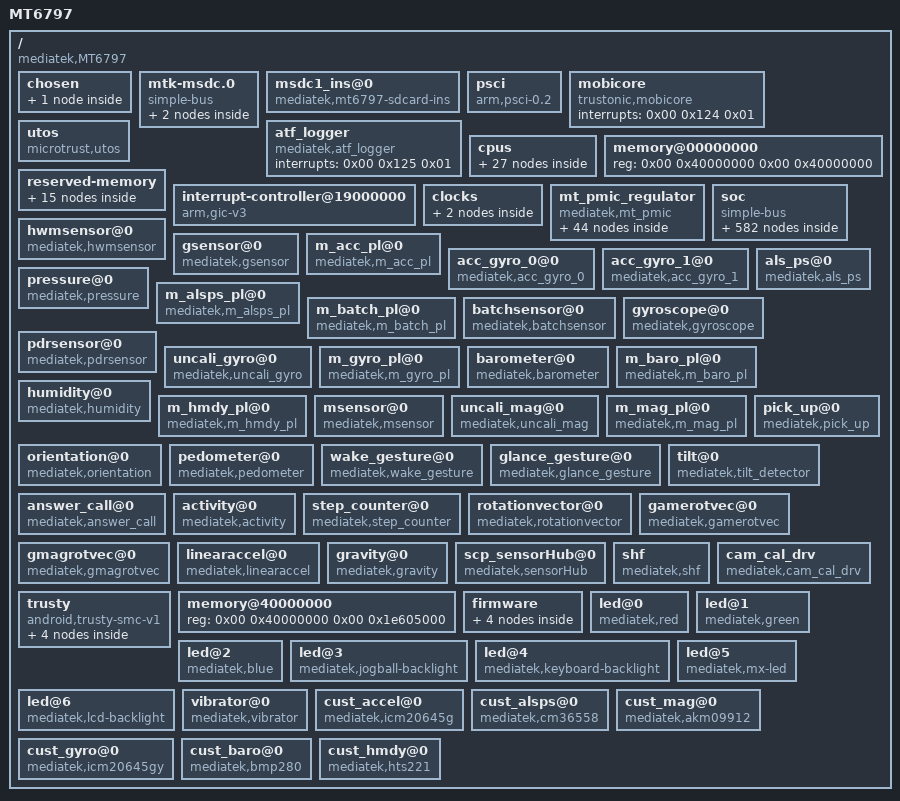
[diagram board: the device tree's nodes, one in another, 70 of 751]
/dts-v1/;

/ {
	model = "MT6797";
	compatible = "mediatek,MT6797";
	interrupt-parent = <0x01>;
	#address-cells = <0x02>;
	#size-cells = <0x02>;

	chosen {
		bootargs = "console=tty0 console=ttyMT0,921600n1 root=/dev/ram initrd=0x44000000,0x4B434E loglevel=8";
		atag,videolfb-fb_base_h = <0x00>;
		atag,videolfb-fb_base_l = "^`P";
		atag,videolfb-islcmfound = <0x01>;
		atag,videolfb-islcm_inited = <0x00>;
		atag,videolfb-fps = <0x1770>;
		atag,videolfb-vramSize = <0x17bb000>;
		atag,videolfb-lcmname = "ft8716_fhd_vdo_sharp";

		linux,sysrq-reset-seq {
			keyset = <0x66 0x72 0x73>;
			timeout-ms = <0x3a98>;
		};
	};

	mtk-msdc.0 {
		compatible = "simple-bus";
		#address-cells = <0x01>;
		#size-cells = <0x01>;
		ranges = <0x00 0x00 0x00 0xffffffff>;

		msdc0@11230000 {
			compatible = "mediatek,mt6797-mmc";
			reg = <0x11230000 0x10000>;
			interrupts = <0x00 0x4f 0x08>;
			clocks = <0x02 0x21>;
			clock-names = "msdc0-clock";
			status = "okay";
			clk_src = [01];
			bus-width = <0x08>;
			max-frequency = <0xbebc200>;
			cap-mmc-highspeed;
			msdc-sys-suspend;
			mmc-ddr-1_8v;
			mmc-hs200-1_8v;
			mmc-hs400-1_8v;
			non-removable;
			pinctl = <0x03>;
			register_setting = <0x04>;
			host_function = [00];
			bootable;
		};

		msdc1@11240000 {
			compatible = "mediatek,mt6797-mmc";
			reg = <0x11240000 0x10000>;
			interrupts = <0x00 0x50 0x08>;
			clocks = <0x02 0x23>;
			clock-names = "msdc1-clock";
			status = "disabled";
			clk_src = [02];
			bus-width = <0x04>;
			max-frequency = <0xbebc200>;
			msdc-sys-suspend;
			cap-sd-highspeed;
			sd-uhs-sdr12;
			sd-uhs-sdr25;
			sd-uhs-sdr50;
			sd-uhs-sdr104;
			pinctl = <0x05>;
			pinctl_sdr104 = <0x06>;
			pinctl_sdr50 = <0x07>;
			pinctl_ddr50 = <0x08>;
			register_setting = <0x09>;
			host_function = [01];
			cd_level = [00];
			cd-gpios = <0x0a 0x43 0x00>;
		};
	};

	msdc1_ins@0 {
		compatible = "mediatek,mt6797-sdcard-ins";
	};

	psci {
		compatible = "arm,psci-0.2";
		method = "smc";
		cpu_suspend = <0x84000001>;
		cpu_off = <0x84000002>;
		cpu_on = <0x84000003>;
		affinity_info = <0x84000004>;
	};

	mobicore {
		compatible = "trustonic,mobicore";
		interrupts = <0x00 0x124 0x01>;
	};

	atf_logger {
		compatible = "mediatek,atf_logger";
		interrupts = <0x00 0x125 0x01>;
	};

	utos {
		compatible = "microtrust,utos";
		interrupts = <0x00 0x126 0x01 0x00 0x127 0x01 0x00 0x128 0x01 0x00 0x12c 0x01 0x00 0x12d 0x01 0x00 0x12e 0x01 0x00 0x12f 0x01 0x00 0x131 0x01>;
	};

	cpus {
		#address-cells = <0x01>;
		#size-cells = <0x00>;

		cpu@000 {
			device_type = "cpu";
			compatible = "arm,cortex-a53";
			reg = <0x00>;
			enable-method = "psci";
			cpu-idle-states = <0x0b 0x0b 0x0b 0x0c 0x0c 0x0c>;
			cpu-release-addr = <0x00 0x40000200>;
			clock-frequency = <0x52e8f9c0>;
			linux,phandle = <0x0d>;
			phandle = <0x0d>;
		};

		cpu@001 {
			device_type = "cpu";
			compatible = "arm,cortex-a53";
			reg = <0x01>;
			enable-method = "psci";
			cpu-idle-states = <0x0b 0x0b 0x0b 0x0c 0x0c 0x0c>;
			cpu-release-addr = <0x00 0x40000200>;
			clock-frequency = <0x52e8f9c0>;
			linux,phandle = <0x0e>;
			phandle = <0x0e>;
		};

		cpu@002 {
			device_type = "cpu";
			compatible = "arm,cortex-a53";
			reg = <0x02>;
			enable-method = "psci";
			cpu-idle-states = <0x0b 0x0b 0x0b 0x0c 0x0c 0x0c>;
			cpu-release-addr = <0x00 0x40000200>;
			clock-frequency = <0x52e8f9c0>;
			linux,phandle = <0x0f>;
			phandle = <0x0f>;
		};

		cpu@003 {
			device_type = "cpu";
			compatible = "arm,cortex-a53";
			reg = <0x03>;
			enable-method = "psci";
			cpu-idle-states = <0x0b 0x0b 0x0b 0x0c 0x0c 0x0c>;
			cpu-release-addr = <0x00 0x40000200>;
			clock-frequency = <0x52e8f9c0>;
			linux,phandle = <0x10>;
			phandle = <0x10>;
		};

		cpu@100 {
			device_type = "cpu";
			compatible = "arm,cortex-a53";
			reg = <0x100>;
			enable-method = "psci";
			cpu-idle-states = <0x0b 0x0b 0x0b 0x0c 0x0c 0x0c>;
			cpu-release-addr = <0x00 0x40000200>;
			clock-frequency = <0x743aa380>;
			linux,phandle = <0x11>;
			phandle = <0x11>;
		};

		cpu@101 {
			device_type = "cpu";
			compatible = "arm,cortex-a53";
			reg = <0x101>;
			enable-method = "psci";
			cpu-idle-states = <0x0b 0x0b 0x0b 0x0c 0x0c 0x0c>;
			cpu-release-addr = <0x00 0x40000200>;
			clock-frequency = <0x743aa380>;
			linux,phandle = <0x12>;
			phandle = <0x12>;
		};

		cpu@102 {
			device_type = "cpu";
			compatible = "arm,cortex-a53";
			reg = <0x102>;
			enable-method = "psci";
			cpu-idle-states = <0x0b 0x0b 0x0b 0x0c 0x0c 0x0c>;
			cpu-release-addr = <0x00 0x40000200>;
			clock-frequency = <0x743aa380>;
			linux,phandle = <0x13>;
			phandle = <0x13>;
		};

		cpu@103 {
			device_type = "cpu";
			compatible = "arm,cortex-a53";
			reg = <0x103>;
			enable-method = "psci";
			cpu-idle-states = <0x0b 0x0b 0x0b 0x0c 0x0c 0x0c>;
			cpu-release-addr = <0x00 0x40000200>;
			clock-frequency = <0x743aa380>;
			linux,phandle = <0x14>;
			phandle = <0x14>;
		};

		cpu@200 {
			device_type = "cpu";
			compatible = "arm,cortex-a72";
			reg = <0x200>;
			enable-method = "psci";
			cpu-idle-states = <0x0b 0x0b 0x0b 0x0c 0x0c 0x0c>;
			cpu-release-addr = <0x00 0x40000200>;
			clock-frequency = <0x88601c00>;
			linux,phandle = <0x15>;
			phandle = <0x15>;
		};

		cpu@201 {
			device_type = "cpu";
			compatible = "arm,cortex-a72";
			reg = <0x201>;
			enable-method = "psci";
			cpu-idle-states = <0x0b 0x0b 0x0b 0x0c 0x0c 0x0c>;
			cpu-release-addr = <0x00 0x40000200>;
			clock-frequency = <0x88601c00>;
			linux,phandle = <0x16>;
			phandle = <0x16>;
		};

		cpu-map {

			cluster0 {

				core0 {
					cpu = <0x0d>;
				};

				core1 {
					cpu = <0x0e>;
				};

				core2 {
					cpu = <0x0f>;
				};

				core3 {
					cpu = <0x10>;
				};
			};

			cluster1 {

				core0 {
					cpu = <0x11>;
				};

				core1 {
					cpu = <0x12>;
				};

				core2 {
					cpu = <0x13>;
				};

				core3 {
					cpu = <0x14>;
				};
			};

			cluster2 {

				core0 {
					cpu = <0x15>;
				};

				core1 {
					cpu = <0x16>;
				};
			};
		};

		idle-states {
			entry-method = "arm,psci";

			cpu-sleep-0-0 {
				compatible = "arm,idle-state";
				arm,psci-suspend-param = <0x10000>;
				entry-latency-us = <0x258>;
				exit-latency-us = <0x258>;
				min-residency-us = <0x4b0>;
				linux,phandle = <0x0c>;
				phandle = <0x0c>;
			};

			cluster-sleep-0 {
				compatible = "arm,idle-state";
				arm,psci-suspend-param = <0x1010000>;
				entry-latency-us = <0x320>;
				exit-latency-us = <0x3e8>;
				min-residency-us = <0x7d0>;
				linux,phandle = <0x0b>;
				phandle = <0x0b>;
			};
		};
	};

	memory@00000000 {
		device_type = "memory";
		reg = <0x00 0x40000000 0x00 0x40000000>;
	};

	reserved-memory {
		#address-cells = <0x02>;
		#size-cells = <0x02>;
		ranges;

		spm-dummy-1@40000000 {
			compatible = "mediatek,spm-dummy-1";
			reg = <0x00 0x40000000 0x00 0x1000>;
		};

		reserve-memory-ccci_md1 {
			compatible = "mediatek,reserve-memory-ccci_md1";
			no-map;
			size = <0x00 0xa100000>;
			alignment = <0x00 0x2000000>;
			alloc-ranges = <0x00 0x40000000 0x00 0x80000000>;
		};

		reserve-memory-ccci_share {
			compatible = "mediatek,reserve-memory-ccci_share";
			no-map;
			size = <0x00 0x600000>;
			alignment = <0x00 0x4000000>;
			alloc-ranges = <0x00 0x40000000 0x00 0x50000000>;
		};

		minirdump-reserved-memory@444f0000 {
			compatible = "minirdump-reserve-memory";
			reg = <0x00 0x444f0000 0x00 0x10000>;
		};

		preloader-reserved-memory@44800000 {
			compatible = "mediatek,preloader";
			reg = <0x00 0x44800000 0x00 0x100000>;
		};

		lk-reserved-memory@46000000 {
			compatible = "mediatek,lk";
			reg = <0x00 0x46000000 0x00 0x400000>;
		};

		ram_console-reserved-memory@44400000 {
			compatible = "ram_console-reserve-memory";
			reg = <0x00 0x44400000 0x00 0x10000>;
		};

		pstore-reserved-memory@44410000 {
			compatible = "mediatek,pstore";
			reg = <0x00 0x44410000 0x00 0xe0000>;
		};

		consys-reserve-memory {
			compatible = "mediatek,consys-reserve-memory";
			no-map;
			size = <0x00 0x200000>;
			alignment = <0x00 0x200000>;
			alloc-ranges = <0x00 0x40000000 0x00 0x80000000>;
		};

		spm-reserve-memory {
			compatible = "mediatek,spm-reserve-memory";
			no-map;
			size = <0x00 0x16000>;
			alignment = <0x00 0x10000>;
			alloc-ranges = <0x00 0x40000000 0x00 0x80000000>;
		};

		atf-reserved-memory@44600000 {
			compatible = "mediatek,mt6797-atf-reserved-memory";
			no-map;
			reg = <0x00 0x44600000 0x00 0x10000>;
		};

		atf-ramdump-memory@44610000 {
			compatible = "mediatek,mt6797-atf-ramdump-memory";
			no-map;
			reg = <0x00 0x44610000 0x00 0x30000>;
		};

		cache-dump-memory@44640000 {
			compatible = "mediatek,cache-dump-memory";
			no-map;
			reg = <0x00 0x44640000 0x00 0x30000>;
		};

		reserve-memory-scp_share {
			compatible = "mediatek,reserve-memory-scp_share";
			no-map;
			size = <0x00 0x1000000>;
			alignment = <0x00 0x1000000>;
			alloc-ranges = <0x00 0x40000000 0x00 0x50000000>;
		};

		memory-lowpower-reserved-memory {
			compatible = "mediatek,memory-lowpower";
			size = <0x00 0x40000000>;
			alloc-ranges = <0x00 0xc0000000 0x00 0x80000000>;
		};
	};

	interrupt-controller@19000000 {
		compatible = "arm,gic-v3";
		#interrupt-cells = <0x03>;
		#address-cells = <0x02>;
		#size-cells = <0x02>;
		#redistributor-regions = <0x01>;
		interrupt-controller;
		reg = <0x00 0x19000000 0x00 0x40000 0x00 0x19200000 0x00 0x200000 0x00 0x10220620 0x00 0x1000 0x00 0x10220690 0x00 0x1000>;
		interrupts = <0x01 0x09 0x04>;
		mediatek,wdt_irq = <0xa9>;
		mediatek,reg_len_pol0 = <0x08>;
		linux,phandle = <0x01>;
		phandle = <0x01>;
	};

	clocks {

		clk_null {
			compatible = "fixed-clock";
			#clock-cells = <0x00>;
			clock-frequency = <0x00>;
		};

		clk26m {
			compatible = "fixed-clock";
			#clock-cells = <0x00>;
			clock-frequency = <0x18cba80>;
			linux,phandle = <0x5b>;
			phandle = <0x5b>;
		};
	};

	mt_pmic_regulator {
		compatible = "mediatek,mt_pmic";

		buck_regulators {
			compatible = "mediatek,mt_pmic_buck_regulators";

			buck_vcore {
				regulator-name = "vcore";
				regulator-min-microvolt = <0x927c0>;
				regulator-max-microvolt = <0x154456>;
				regulator-ramp-delay = <0x186a>;
				regulator-enable-ramp-delay = <0xb4>;
			};

			buck_vgpu {
				regulator-name = "vgpu";
				regulator-min-microvolt = <0x927c0>;
				regulator-max-microvolt = <0x154456>;
				regulator-ramp-delay = <0x186a>;
				regulator-enable-ramp-delay = <0xb4>;
				regulator-always-on;
				regulator-boot-on;
			};

			buck_vmodem {
				regulator-name = "vmodem";
				regulator-min-microvolt = <0x927c0>;
				regulator-max-microvolt = <0x154456>;
				regulator-ramp-delay = <0x186a>;
				regulator-enable-ramp-delay = <0xb4>;
				regulator-always-on;
				regulator-boot-on;
			};

			buck_vmd1 {
				regulator-name = "vmd1";
				regulator-min-microvolt = <0x927c0>;
				regulator-max-microvolt = <0x154456>;
				regulator-ramp-delay = <0x186a>;
				regulator-enable-ramp-delay = <0xb4>;
				regulator-always-on;
				regulator-boot-on;
			};

			buck_vsram_md {
				regulator-name = "vsram_md";
				regulator-min-microvolt = <0x927c0>;
				regulator-max-microvolt = <0x154456>;
				regulator-ramp-delay = <0x186a>;
				regulator-enable-ramp-delay = <0xb4>;
				regulator-always-on;
				regulator-boot-on;
			};

			buck_vs1 {
				regulator-name = "vs1";
				regulator-min-microvolt = <0x927c0>;
				regulator-max-microvolt = <0x154456>;
				regulator-ramp-delay = <0x186a>;
				regulator-enable-ramp-delay = <0xb4>;
				regulator-always-on;
				regulator-boot-on;
			};

			buck_vs2 {
				regulator-name = "vs2";
				regulator-min-microvolt = <0x927c0>;
				regulator-max-microvolt = <0x154456>;
				regulator-ramp-delay = <0x186a>;
				regulator-enable-ramp-delay = <0xb4>;
				regulator-always-on;
				regulator-boot-on;
			};

			buck_vpa {
				regulator-name = "vpa";
				regulator-min-microvolt = <0x927c0>;
				regulator-max-microvolt = <0x154456>;
				regulator-ramp-delay = <0x186a>;
				regulator-enable-ramp-delay = <0xb4>;
				regulator-always-on;
				regulator-boot-on;
			};

			buck_vsram_proc {
				regulator-name = "vsram_proc";
				regulator-min-microvolt = <0x927c0>;
				regulator-max-microvolt = <0x154456>;
				regulator-ramp-delay = <0x186a>;
				regulator-enable-ramp-delay = <0xb4>;
				regulator-always-on;
				regulator-boot-on;
			};
		};

		ldo_regulators {
			compatible = "mediatek,mt_pmic_ldo_regulators";

			ldo_va18 {
				regulator-name = "va18";
				regulator-min-microvolt = <0x1b7740>;
				regulator-max-microvolt = <0x1b7740>;
				regulator-enable-ramp-delay = <0x108>;
				regulator-boot-on;
				linux,phandle = <0x17>;
				phandle = <0x17>;
			};

			ldo_vtcxo24 {
				regulator-name = "vtcxo24";
				regulator-min-microvolt = <0x1b7740>;
				regulator-max-microvolt = <0x2ab980>;
				regulator-enable-ramp-delay = <0x6e>;
				regulator-boot-on;
				linux,phandle = <0x18>;
				phandle = <0x18>;
			};

			ldo_vtcxo28 {
				regulator-name = "vtcxo28";
				regulator-min-microvolt = <0x1b7740>;
				regulator-max-microvolt = <0x2ab980>;
				regulator-enable-ramp-delay = <0x6e>;
				linux,phandle = <0x19>;
				phandle = <0x19>;
			};

			ldo_vcn28 {
				regulator-name = "vcn28";
				regulator-min-microvolt = <0x1b7740>;
				regulator-max-microvolt = <0x2ab980>;
				regulator-enable-ramp-delay = <0x108>;
				linux,phandle = <0x2b>;
				phandle = <0x2b>;
			};

			ldo_vcama {
				regulator-name = "vcama";
				regulator-min-microvolt = <0x16e360>;
				regulator-max-microvolt = <0x2ab980>;
				regulator-enable-ramp-delay = <0x108>;
				regulator-default-on = <0x01>;
				status = "okay";
				linux,phandle = <0x7d>;
				phandle = <0x7d>;
			};

			ldo_vusb33 {
				regulator-name = "vusb33";
				regulator-min-microvolt = <0x325aa0>;
				regulator-max-microvolt = <0x325aa0>;
				regulator-enable-ramp-delay = <0x108>;
				regulator-boot-on;
			};

			ldo_vsim1 {
				regulator-name = "vsim1";
				regulator-min-microvolt = <0x19f0a0>;
				regulator-max-microvolt = <0x2f4d60>;
				regulator-enable-ramp-delay = <0x108>;
				regulator-default-on = <0x01>;
				status = "okay";
				linux,phandle = <0x1a>;
				phandle = <0x1a>;
			};

			ldo_vsim2 {
				regulator-name = "vsim2";
				regulator-min-microvolt = <0x19f0a0>;
				regulator-max-microvolt = <0x2f4d60>;
				regulator-enable-ramp-delay = <0x108>;
				regulator-default-on = <0x01>;
				status = "okay";
				linux,phandle = <0x1b>;
				phandle = <0x1b>;
			};

			ldo_vemc {
				regulator-name = "vemc_3v3";
				regulator-min-microvolt = <0x2dc6c0>;
				regulator-max-microvolt = <0x325aa0>;
				regulator-enable-ramp-delay = <0x2c>;
				regulator-boot-on;
				linux,phandle = <0x1c>;
				phandle = <0x1c>;
			};

			ldo_vmch {
				regulator-name = "vmch";
				regulator-min-microvolt = <0x2dc6c0>;
				regulator-max-microvolt = <0x325aa0>;
				regulator-enable-ramp-delay = <0x2c>;
				linux,phandle = <0x1d>;
				phandle = <0x1d>;
			};

			ldo_vio28 {
				regulator-name = "vio28";
				regulator-min-microvolt = <0x2ab980>;
				regulator-max-microvolt = <0x2ab980>;
				regulator-enable-ramp-delay = <0x108>;
				regulator-boot-on;
				linux,phandle = <0x1f>;
				phandle = <0x1f>;
			};

			ldo_vibr {
				regulator-name = "vibr";
				regulator-min-microvolt = <0x124f80>;
				regulator-max-microvolt = <0x325aa0>;
				regulator-enable-ramp-delay = <0x2c>;
				regulator-default-on = <0x01>;
				status = "okay";
				linux,phandle = <0x20>;
				phandle = <0x20>;
			};

			ldo_vcamd {
				regulator-name = "vcamd";
				regulator-min-microvolt = <0xdbba0>;
				regulator-max-microvolt = <0x127690>;
				regulator-enable-ramp-delay = <0x108>;
				regulator-default-on = <0x01>;
				status = "okay";
				linux,phandle = <0x7e>;
				phandle = <0x7e>;
			};

			ldo_vrf18 {
				regulator-name = "vrf18";
				regulator-min-microvolt = <0xf4240>;
				regulator-max-microvolt = <0x1b9e50>;
				regulator-enable-ramp-delay = <0xdc>;
				linux,phandle = <0x21>;
				phandle = <0x21>;
			};

			ldo_vio18 {
				regulator-name = "vio18";
				regulator-min-microvolt = <0x1b7740>;
				regulator-max-microvolt = <0x1b7740>;
				regulator-enable-ramp-delay = <0x108>;
				regulator-boot-on;
				linux,phandle = <0x22>;
				phandle = <0x22>;
			};

			ldo_vcn18 {
				regulator-name = "vcn18";
				regulator-min-microvolt = <0x1b7740>;
				regulator-max-microvolt = <0x1b7740>;
				regulator-enable-ramp-delay = <0x2c>;
				linux,phandle = <0x2a>;
				phandle = <0x2a>;
			};

			ldo_vcamio {
				regulator-name = "vcamio";
				regulator-min-microvolt = <0x124f80>;
				regulator-max-microvolt = <0x1b7740>;
				regulator-enable-ramp-delay = <0xdc>;
				regulator-default-on = <0x01>;
				status = "okay";
				linux,phandle = <0x80>;
				phandle = <0x80>;
			};

			ldo_vsram_proc {
				regulator-name = "vsram_proc";
				regulator-min-microvolt = <0x927c0>;
				regulator-max-microvolt = <0x154456>;
				regulator-enable-ramp-delay = <0xdc>;
				regulator-boot-on;
				linux,phandle = <0x23>;
				phandle = <0x23>;
			};

			ldo_vxo22 {
				regulator-name = "vxo22";
				regulator-min-microvolt = <0x1b7740>;
				regulator-max-microvolt = <0x2ab980>;
				regulator-enable-ramp-delay = <0x6e>;
				regulator-boot-on;
				linux,phandle = <0x24>;
				phandle = <0x24>;
			};

			ldo_vrf12 {
				regulator-name = "vrf12";
				regulator-min-microvolt = <0xdbba0>;
				regulator-max-microvolt = <0x124f80>;
				regulator-enable-ramp-delay = <0xdc>;
				linux,phandle = <0x25>;
				phandle = <0x25>;
			};

			ldo_va10 {
				regulator-name = "va10";
				regulator-min-microvolt = <0xdbba0>;
				regulator-max-microvolt = <0x1b7740>;
				regulator-enable-ramp-delay = <0x108>;
				regulator-boot-on;
			};

			ldo_vdram {
				regulator-name = "vdram";
				regulator-min-microvolt = <0xdbba0>;
				regulator-max-microvolt = <0x127690>;
				regulator-enable-ramp-delay = <0x108>;
				linux,phandle = <0x26>;
				phandle = <0x26>;
			};

			ldo_vmipi {
				regulator-name = "vmipi";
				regulator-min-microvolt = <0xdbba0>;
				regulator-max-microvolt = <0x1b7740>;
				regulator-enable-ramp-delay = <0x108>;
				linux,phandle = <0x27>;
				phandle = <0x27>;
			};

			ldo_vgp3 {
				regulator-name = "vgp3";
				regulator-min-microvolt = <0xf4240>;
				regulator-max-microvolt = <0x1b9e50>;
				regulator-enable-ramp-delay = <0x108>;
				regulator-default-on = <0x00>;
				status = "okay";
				linux,phandle = <0x2e>;
				phandle = <0x2e>;
			};

			ldo_vbif28 {
				regulator-name = "vbif28";
				regulator-min-microvolt = <0x2ab980>;
				regulator-max-microvolt = <0x2ab980>;
				regulator-enable-ramp-delay = <0x108>;
				linux,phandle = <0x28>;
				phandle = <0x28>;
			};

			ldo_vefuse {
				regulator-name = "vefuse";
				regulator-min-microvolt = <0x124f80>;
				regulator-max-microvolt = <0x2191c0>;
				regulator-enable-ramp-delay = <0x108>;
				linux,phandle = <0x29>;
				phandle = <0x29>;
			};

			ldo_vcn33_bt {
				regulator-name = "vcn33_bt";
				regulator-min-microvolt = <0x325aa0>;
				regulator-max-microvolt = <0x36ee80>;
				regulator-enable-ramp-delay = <0x108>;
				linux,phandle = <0x2c>;
				phandle = <0x2c>;
			};

			ldo_vcn33_wifi {
				regulator-name = "vcn33_wifi";
				regulator-min-microvolt = <0x325aa0>;
				regulator-max-microvolt = <0x36ee80>;
				regulator-enable-ramp-delay = <0x108>;
				linux,phandle = <0x2d>;
				phandle = <0x2d>;
			};

			ldo_vldo28 {
				regulator-name = "vldo28";
				regulator-min-microvolt = <0x2ab980>;
				regulator-max-microvolt = <0x2ab980>;
				regulator-enable-ramp-delay = <0x108>;
				regulator-default-on = <0x01>;
				status = "okay";
				linux,phandle = <0x7f>;
				phandle = <0x7f>;
			};

			ldo_vmc {
				regulator-name = "vmc";
				regulator-min-microvolt = <0x124f80>;
				regulator-max-microvolt = <0x325aa0>;
				regulator-enable-ramp-delay = <0x2c>;
				linux,phandle = <0x1e>;
				phandle = <0x1e>;
			};

			ldo_vldo28_0 {
				regulator-name = "vldo28_0";
				regulator-min-microvolt = <0x2ab980>;
				regulator-max-microvolt = <0x2ab980>;
				regulator-enable-ramp-delay = <0x108>;
			};

			ldo_vldo28_1 {
				regulator-name = "vldo28_1";
				regulator-min-microvolt = <0x2ab980>;
				regulator-max-microvolt = <0x2ab980>;
				regulator-enable-ramp-delay = <0x108>;
			};
		};

		regulators_supply {
			compatible = "mediatek,mt_pmic_regulator_supply";
			va18-supply = <0x17>;
			vtcxo24-supply = <0x18>;
			vtcxo28-supply = <0x19>;
			vsim1-supply = <0x1a>;
			vsim2-supply = <0x1b>;
			vemc-supply = <0x1c>;
			vmch-supply = <0x1d>;
			vmc-supply = <0x1e>;
			vio28-supply = <0x1f>;
			vibr-supply = <0x20>;
			vrf18-supply = <0x21>;
			vio18-supply = <0x22>;
			vsram_proc-supply = <0x23>;
			vxo22-supply = <0x24>;
			vrf12-supply = <0x25>;
			vdram-supply = <0x26>;
			vmipi-supply = <0x27>;
			vbif28-supply = <0x28>;
			vefuse-supply = <0x29>;
			vcn18-supply = <0x2a>;
			vcn28-supply = <0x2b>;
			vcn33_bt-supply = <0x2c>;
			vcn33_wifi-supply = <0x2d>;
			mhl_12v-supply = <0x2e>;
		};
	};

	soc {
		compatible = "simple-bus";
		#address-cells = <0x01>;
		#size-cells = <0x01>;
		ranges = <0x00 0x00 0x00 0xffffffff>;

		chipid@08000000 {
			compatible = "mediatek,chipid";
			reg = <0x8000000 0x04 0x8000004 0x04 0x8000008 0x04 0x800000c 0x04>;
		};

		topckgen@10000000 {
			compatible = "mediatek,topckgen";
			reg = <0x10000000 0x1000>;
			#clock-cells = <0x01>;
			linux,phandle = <0x59>;
			phandle = <0x59>;
		};

		power_gs@10000000 {
			compatible = "mediatek,mt6797-power_gs";
			reg = <0x10000000 0x11001 0x12000000 0x8001011>;
		};

		usb2jtag@10001000 {
			compatible = "mediatek,usb2jtag_v1";
			reg = <0x10001000 0x1000 0x11290000 0x1000>;
		};

		infracfg_ao@10001000 {
			compatible = "mediatek,infracfg_ao";
			reg = <0x10001000 0x1000>;
			#clock-cells = <0x01>;
			linux,phandle = <0x02>;
			phandle = <0x02>;
		};

		scpsys@10001000 {
			compatible = "mediatek,mt6797-scpsys";
			reg = <0x10001000 0x1000 0x10006000 0x1000 0x10201000 0x1000>;
			#clock-cells = <0x01>;
			linux,phandle = <0x34>;
			phandle = <0x34>;
		};

		btcvsd@10001000 {
			compatible = "mediatek,audio_bt_cvsd";
			offset = <0xf00 0x800 0xfd0 0xfd4 0xfd8>;
			reg = <0x10001000 0x1000 0x18000000 0x10000 0x18080000 0x8000>;
			interrupts = <0x00 0x11e 0x08>;
		};

		mt_soc_btcvsd_rx_pcm@10001000 {
			compatible = "mediatek,mt_soc_btcvsd_rx_pcm";
		};

		mt_soc_btcvsd_tx_pcm@10001000 {
			compatible = "mediatek,mt_soc_btcvsd_tx_pcm";
		};

		iocfg_l@10002000 {
			compatible = "mediatek,iocfg_l";
			reg = <0x10002000 0x400>;
		};

		iocfg_b@10002400 {
			compatible = "mediatek,iocfg_b";
			reg = <0x10002400 0x400>;
		};

		iocfg_r@10002800 {
			compatible = "mediatek,iocfg_r";
			reg = <0x10002800 0x400>;
		};

		iocfg_t@10002c00 {
			compatible = "mediatek,iocfg_t";
			reg = <0x10002c00 0x400>;
		};

		pericfg@10003000 {
			compatible = "mediatek,pericfg";
			reg = <0x10003000 0x1000>;
		};

		dramc_conf@10004000 {
			compatible = "mediatek,dramc";
			reg = <0x10004000 0x1000>;
		};

		gpio {
			compatible = "mediatek,gpio_usage_mapping";
			GPIO_FDD_BAND_SUPPORT_DETECT_1ST_PIN = <0x2a>;
			GPIO_SIM1_HOT_PLUG = <0x70>;
			GPIO_SIM1_SCLK = <0x7e>;
			GPIO_SIM1_SRST = <0x7f>;
			GPIO_SIM1_SIO = <0x80>;
			GPIO_SIM2_SCLK = <0x9b>;
			GPIO_SIM2_SRST = <0x9c>;
			GPIO_SIM2_SIO = <0x9d>;
		};

		gpio@10005000 {
			compatible = "mediatek,gpio";
			reg = <0x10005000 0x1000>;
			pinctrl-names = "system_setup_default\0system_suspend\0system_resume";
			pinctrl-0 = <0x2f>;
			pinctrl-1 = <0x30>;
			pinctrl-2 = <0x31>;
			status = "okay";
		};

		syscfg_pctl_a@10005000 {
			compatible = "mediatek,mt6797-pctl-a-syscfg\0syscon";
			reg = <0x10005000 0x1000>;
			linux,phandle = <0x32>;
			phandle = <0x32>;
		};

		pinctrl@10005000 {
			compatible = "mediatek,mt6797-pinctrl";
			reg = <0x10005000 0x1000>;
			mediatek,pctl-regmap = <0x32>;
			pins-are-numbered;
			gpio-controller;
			#gpio-cells = <0x02>;
			linux,phandle = <0x0a>;
			phandle = <0x0a>;

			alspspincfg {
				linux,phandle = <0xb0>;
				phandle = <0xb0>;

				pins_cmd_dat {
					pins = <0x5501>;
					slew-rate = <0x00>;
					bias-pull-up = <0x00>;
				};
			};

			alspsdefaultcfg {
				linux,phandle = <0xaf>;
				phandle = <0xaf>;
			};

			gyropincfg {
				linux,phandle = <0xb2>;
				phandle = <0xb2>;

				pins_cmd_dat {
					pins = <0x3f01>;
					slew-rate = <0x00>;
					bias-pull-down = <0x00>;
				};
			};

			gyrodefaultcfg {
				linux,phandle = <0xb1>;
				phandle = <0xb1>;
			};

			uart0gpiodefault {
				linux,phandle = <0x3e>;
				phandle = <0x3e>;
			};

			uart0_rx_set@gpio97 {
				linux,phandle = <0x3f>;
				phandle = <0x3f>;

				pins_cmd_dat {
					pins = <0x6101>;
				};
			};

			uart0_rx_clear@gpio97 {
				linux,phandle = <0x40>;
				phandle = <0x40>;

				pins_cmd_dat {
					pins = <0x6100>;
					slew-rate = <0x01>;
					output-high;
				};
			};

			uart0_tx_set@gpio98 {
				linux,phandle = <0x41>;
				phandle = <0x41>;

				pins_cmd_dat {
					pins = <0x6201>;
				};
			};

			uart0_tx_clear@gpio98 {
				linux,phandle = <0x42>;
				phandle = <0x42>;

				pins_cmd_dat {
					pins = <0x6200>;
					slew-rate = <0x01>;
					output-high;
				};
			};

			state_default {
				linux,phandle = <0xa3>;
				phandle = <0xa3>;
			};

			state_miso_spi {
				linux,phandle = <0xa4>;
				phandle = <0xa4>;

				pins_cmd_dat {
					pins = <0xeb01>;
				};
			};

			state_miso_pullhigh {
				linux,phandle = <0xa5>;
				phandle = <0xa5>;

				pins_cmd_dat {
					pins = <0xeb00>;
					slew-rate = <0x01>;
					output-high;
				};
			};

			state_miso_pulllow {
				linux,phandle = <0xa6>;
				phandle = <0xa6>;

				pins_cmd_dat {
					pins = <0xeb00>;
					slew-rate = <0x01>;
					output-low;
				};
			};

			state_reset_high {
				linux,phandle = <0xa7>;
				phandle = <0xa7>;

				pins_cmd_dat {
					pins = <0xfd00>;
					slew-rate = <0x01>;
					output-high;
				};
			};

			state_reset_low {
				linux,phandle = <0xa8>;
				phandle = <0xa8>;

				pins_cmd_dat {
					pins = <0xfd00>;
					slew-rate = <0x01>;
					output-low;
				};
			};

			eint0default {
				linux,phandle = <0x94>;
				phandle = <0x94>;
			};

			eint@0 {
				linux,phandle = <0x95>;
				phandle = <0x95>;

				pins_cmd_dat {
					pins = <0x4401>;
					slew-rate = <0x00>;
					bias-pull-up = <0x00>;
				};
			};

			eintoutput0 {
				linux,phandle = <0x96>;
				phandle = <0x96>;

				pins_cmd_dat {
					pins = <0x4400>;
					slew-rate = <0x00>;
					bias-pull-down = <0x00>;
				};
			};

			eintoutput1 {
				linux,phandle = <0x97>;
				phandle = <0x97>;

				pins_cmd_dat {
					pins = <0x4400>;
					slew-rate = <0x00>;
					bias-pull-up = <0x00>;
				};
			};

			rstoutput0 {
				linux,phandle = <0x98>;
				phandle = <0x98>;

				pins_cmd_dat {
					pins = <0xd300>;
					slew-rate = <0x01>;
					output-low;
				};
			};

			rstoutput1 {
				linux,phandle = <0x99>;
				phandle = <0x99>;

				pins_cmd_dat {
					pins = <0xd300>;
					slew-rate = <0x01>;
					output-high;
				};
			};

			accdetdefault {
				linux,phandle = <0x9a>;
				phandle = <0x9a>;
			};

			accdeteint@0 {
				linux,phandle = <0x9b>;
				phandle = <0x9b>;

				pins_cmd_dat {
					pins = <0x5c01>;
					slew-rate = <0x00>;
					bias-disable;
				};
			};

			default_configuration {
				linux,phandle = <0x2f>;
				phandle = <0x2f>;
			};

			suspend_configuration {
				linux,phandle = <0x30>;
				phandle = <0x30>;

				pins_cmd1_dat {
					pins = <0x2700>;
					slew-rate = <0x00>;
					bias-disable;
				};

				pins_cmd2_dat {
					pins = <0x2800>;
					slew-rate = <0x00>;
					bias-disable;
				};

				pins_cmd3_dat {
					pins = <0x2900>;
					slew-rate = <0x00>;
					bias-disable;
				};

				pins_cmd4_dat {
					pins = <0x2a00>;
					slew-rate = <0x00>;
					bias-disable;
				};

				pins_cmd5_dat {
					pins = <0x3500>;
					slew-rate = <0x00>;
					bias-disable;
				};

				pins_cmd6_dat {
					pins = <0x3600>;
					slew-rate = <0x00>;
					bias-disable;
				};

				pins_cmd7_dat {
					pins = <0x5a00>;
					slew-rate = <0x00>;
					bias-disable;
				};
			};

			resume_configuration {
				linux,phandle = <0x31>;
				phandle = <0x31>;

				pins_cmd7_dat {
					pins = <0x5a01>;
					bias-pull-up = <0x00>;
				};
			};

			aud_clk_mosi_off {
				linux,phandle = <0x5c>;
				phandle = <0x5c>;

				pins_cmd0_dat {
					pins = <0x9200>;
				};
			};

			aud_clk_mosi_on {
				linux,phandle = <0x5d>;
				phandle = <0x5d>;

				pins_cmd0_dat {
					pins = <0x9201>;
				};
			};

			aud_pins_smartpa_mode0 {
				linux,phandle = <0x5e>;
				phandle = <0x5e>;

				pins_cmd0_dat {
					pins = <0x4500>;
				};

				pins_cmd1_dat {
					pins = <0x4600>;
				};

				pins_cmd2_dat {
					pins = <0x4800>;
				};

				pins_cmd3_dat {
					pins = <0x4900>;
				};
			};

			aud_pins_smartpa_mode1 {
				linux,phandle = <0x5f>;
				phandle = <0x5f>;

				pins_cmd0_dat {
					pins = <0x4501>;
				};

				pins_cmd1_dat {
					pins = <0x4601>;
				};

				pins_cmd2_dat {
					pins = <0x4802>;
				};

				pins_cmd3_dat {
					pins = <0x4902>;
				};
			};

			aud_pins_smartpa_mode2 {
				linux,phandle = <0x6f>;
				phandle = <0x6f>;

				pins_cmd0_dat {
					pins = <0x4502>;
				};

				pins_cmd1_dat {
					pins = <0x4602>;
				};

				pins_cmd2_dat {
					pins = <0x4802>;
				};

				pins_cmd3_dat {
					pins = <0x4902>;
				};
			};

			aud_pins_smartpa_mode3 {
				linux,phandle = <0x60>;
				phandle = <0x60>;

				pins_cmd0_dat {
					pins = <0x4503>;
				};

				pins_cmd1_dat {
					pins = <0x4603>;
				};

				pins_cmd2_dat {
					pins = <0x4804>;
				};

				pins_cmd3_dat {
					pins = <0x4904>;
				};
			};

			aud_pins_tdm_mode0 {
				linux,phandle = <0x61>;
				phandle = <0x61>;
			};

			aud_pins_tdm_mode1 {
				linux,phandle = <0x62>;
				phandle = <0x62>;
			};

			audhpdepophigh {
				linux,phandle = <0x63>;
				phandle = <0x63>;

				pins_cmd_dat {
					pins = <0xfe00>;
					slew-rate = <0x01>;
					output-high;
				};
			};

			audhpdepoplow {
				linux,phandle = <0x64>;
				phandle = <0x64>;

				pins_cmd_dat {
					pins = <0xfe00>;
					slew-rate = <0x01>;
					output-low;
				};
			};

			aud_dat_miso_off {
				linux,phandle = <0x65>;
				phandle = <0x65>;

				pins_cmd1_dat {
					pins = <0x9300>;
				};
			};

			aud_dat_miso_on {
				linux,phandle = <0x66>;
				phandle = <0x66>;

				pins_cmd1_dat {
					pins = <0x9301>;
				};
			};

			aud_dat_mosi_off {
				linux,phandle = <0x67>;
				phandle = <0x67>;

				pins_cmd2_dat {
					pins = <0x9400>;
				};
			};

			aud_dat_mosi_on {
				linux,phandle = <0x68>;
				phandle = <0x68>;

				pins_cmd2_dat {
					pins = <0x9401>;
				};
			};

			vow_dat_miso_off {
				linux,phandle = <0x69>;
				phandle = <0x69>;

				pins_cmd1_dat {
					pins = <0x9300>;
				};
			};

			vow_dat_miso_on {
				linux,phandle = <0x6a>;
				phandle = <0x6a>;

				pins_cmd1_dat {
					pins = <0x9303>;
				};
			};

			vow_clk_miso_off {
				linux,phandle = <0x6b>;
				phandle = <0x6b>;

				pins_cmd3_dat {
					pins = <0x9500>;
				};
			};

			vow_clk_miso_on {
				linux,phandle = <0x6c>;
				phandle = <0x6c>;

				pins_cmd3_dat {
					pins = <0x9501>;
				};
			};

			anc_dat_mosi_off {
				linux,phandle = <0x6d>;
				phandle = <0x6d>;

				pins_cmd4_dat {
					pins = <0x9600>;
				};
			};

			anc_dat_mosi_on {
				linux,phandle = <0x6e>;
				phandle = <0x6e>;

				pins_cmd4_dat {
					pins = <0x9601>;
				};
			};

			tfa@0 {
				linux,phandle = <0x52>;
				phandle = <0x52>;

				pins_cmd_dat {
					pins = <0xff00>;
					slew-rate = <0x01>;
					output-low;
				};
			};

			tfa@1 {
				linux,phandle = <0x53>;
				phandle = <0x53>;

				pins_cmd_dat {
					pins = <0xff00>;
					slew-rate = <0x01>;
					output-high;
				};
			};

			tfa@2 {
				linux,phandle = <0x54>;
				phandle = <0x54>;

				pins_cmd_dat {
					pins = <0x4700>;
					slew-rate = <0x00>;
					bias-disable;
				};
			};

			mode_te_gpio {
				linux,phandle = <0x8a>;
				phandle = <0x8a>;

				pins_cmd_dat {
					pins = <0xb301>;
				};
			};

			mode_te_te {
				linux,phandle = <0x8b>;
				phandle = <0x8b>;

				pins_cmd_dat {
					pins = <0xb301>;
				};
			};

			lcm_rst_out0_gpio {
				linux,phandle = <0x8c>;
				phandle = <0x8c>;

				pins_cmd_dat {
					pins = <0xb400>;
					slew-rate = <0x01>;
					output-low;
				};
			};

			lcm_rst_out1_gpio {
				linux,phandle = <0x8d>;
				phandle = <0x8d>;

				pins_cmd_dat {
					pins = <0xb400>;
					slew-rate = <0x01>;
					output-high;
				};
			};

			lcd_bias_enp0_gpio {
				linux,phandle = <0xac>;
				phandle = <0xac>;

				pins_cmd_dat {
					pins = <0xfc00>;
					slew-rate = <0x01>;
					output-low;
				};
			};

			lcd_bias_enp1_gpio {
				linux,phandle = <0xab>;
				phandle = <0xab>;

				pins_cmd_dat {
					pins = <0xfc00>;
					slew-rate = <0x01>;
					output-high;
				};
			};

			lcd_dvdd1v8_on_gpio {
				linux,phandle = <0xa9>;
				phandle = <0xa9>;

				pins_cmd_dat {
					pins = <0xc900>;
					slew-rate = <0x01>;
					output-high;
				};
			};

			lcd_dvdd1v8_off_gpio {
				linux,phandle = <0xaa>;
				phandle = <0xaa>;

				pins_cmd_dat {
					pins = <0xc900>;
					slew-rate = <0x01>;
					output-low;
				};
			};

			lcd_bias_enn0_gpio {
				linux,phandle = <0xae>;
				phandle = <0xae>;

				pins_cmd_dat {
					pins = <0xfb00>;
					slew-rate = <0x01>;
					output-low;
				};
			};

			lcd_bias_enn1_gpio {
				linux,phandle = <0xad>;
				phandle = <0xad>;

				pins_cmd_dat {
					pins = <0xfb00>;
					slew-rate = <0x01>;
					output-high;
				};
			};

			cam0@0 {
				linux,phandle = <0x82>;
				phandle = <0x82>;

				pins_cmd_dat {
					pins = <0x2100>;
					slew-rate = <0x01>;
					output-low;
				};
			};

			cam0@1 {
				linux,phandle = <0x83>;
				phandle = <0x83>;

				pins_cmd_dat {
					pins = <0x2100>;
					slew-rate = <0x01>;
					output-high;
				};
			};

			cam0@2 {
				linux,phandle = <0x84>;
				phandle = <0x84>;

				pins_cmd_dat {
					pins = <0x8c00>;
					slew-rate = <0x01>;
					output-low;
				};
			};

			cam0@3 {
				linux,phandle = <0x85>;
				phandle = <0x85>;

				pins_cmd_dat {
					pins = <0x8c00>;
					slew-rate = <0x01>;
					output-high;
				};
			};

			cam1@0 {
				linux,phandle = <0x86>;
				phandle = <0x86>;

				pins_cmd_dat {
					pins = <0x2300>;
					slew-rate = <0x01>;
					output-low;
				};
			};

			cam1@1 {
				linux,phandle = <0x87>;
				phandle = <0x87>;

				pins_cmd_dat {
					pins = <0x2300>;
					slew-rate = <0x01>;
					output-high;
				};
			};

			cam0@vcama0 {
				linux,phandle = <0x88>;
				phandle = <0x88>;

				pins_cmd_dat {
					pins = <0x1e00>;
					slew-rate = <0x01>;
					output-low;
				};
			};

			cam1@vcama1 {
				linux,phandle = <0x89>;
				phandle = <0x89>;

				pins_cmd_dat {
					pins = <0x1e00>;
					slew-rate = <0x01>;
					output-high;
				};
			};

			camdefault {
				linux,phandle = <0x81>;
				phandle = <0x81>;
			};

			consys_pins_default {
				linux,phandle = <0x79>;
				phandle = <0x79>;
			};

			gpslna@0 {
				linux,phandle = <0x7a>;
				phandle = <0x7a>;

				pins_cmd_dat {
					pins = <0x8d00>;
					slew-rate = <0x00>;
					bias-disable;
					output-low;
				};
			};

			gpslna@1 {
				linux,phandle = <0x7b>;
				phandle = <0x7b>;

				pins_cmd_dat {
					pins = <0x8d00>;
					slew-rate = <0x01>;
					output-high;
				};
			};

			gpslna@2 {
				linux,phandle = <0x7c>;
				phandle = <0x7c>;

				pins_cmd_dat {
					pins = <0x8d00>;
					slew-rate = <0x01>;
					output-low;
				};
			};

			flashlight_pins_default {
				linux,phandle = <0x9c>;
				phandle = <0x9c>;
			};

			irtx_gpio_led_def@gpio137 {
				linux,phandle = <0xb3>;
				phandle = <0xb3>;

				pins_cmd_dat {
					pins = <0x8900>;
					slew-rate = <0x00>;
					bias-pull-down = <0x00>;
					input-schmitt-enable = <0x00>;
				};
			};

			irtx_gpio_led_set@gpio137 {
				linux,phandle = <0xb4>;
				phandle = <0xb4>;

				pins_cmd_dat {
					pins = <0x8905>;
				};
			};

			hwen_high {
				linux,phandle = <0x9d>;
				phandle = <0x9d>;

				pins_cmd_dat {
					pins = <0xc200>;
					slew-rate = <0x01>;
					output-high;
				};
			};

			hwen_low {
				linux,phandle = <0x9e>;
				phandle = <0x9e>;

				pins_cmd_dat {
					pins = <0xc200>;
					slew-rate = <0x01>;
					output-low;
				};
			};

			torch_high {
				linux,phandle = <0x9f>;
				phandle = <0x9f>;

				pins_cmd_dat {
					pins = <0xd600>;
					slew-rate = <0x01>;
					output-high;
				};
			};

			torch_low {
				linux,phandle = <0xa0>;
				phandle = <0xa0>;

				pins_cmd_dat {
					pins = <0xd600>;
					slew-rate = <0x01>;
					output-low;
				};
			};

			flash_high {
				linux,phandle = <0xa1>;
				phandle = <0xa1>;

				pins_cmd_dat {
					pins = <0xd000>;
					slew-rate = <0x01>;
					output-high;
				};
			};

			flash_low {
				linux,phandle = <0xa2>;
				phandle = <0xa2>;

				pins_cmd_dat {
					pins = <0xd000>;
					slew-rate = <0x01>;
					output-low;
				};
			};

			iddig_default {
				linux,phandle = <0x70>;
				phandle = <0x70>;
			};

			iddig_init {
				linux,phandle = <0x71>;
				phandle = <0x71>;

				pins_cmd_dat {
					pins = <0xb501>;
					slew-rate = <0x00>;
					bias-pull-up = <0x00>;
				};
			};

			drvvbus_default {
				linux,phandle = <0x72>;
				phandle = <0x72>;
			};

			drvvbus_low {
				linux,phandle = <0x73>;
				phandle = <0x73>;

				pins_cmd_dat {
					pins = <0x5e01>;
					slew-rate = <0x01>;
					output-low;
				};
			};

			drvvbus_high {
				linux,phandle = <0x74>;
				phandle = <0x74>;

				pins_cmd_dat {
					pins = <0x5e01>;
					slew-rate = <0x01>;
					output-high;
				};
			};

			chg0_dis_low_cfg {
				linux,phandle = <0x43>;
				phandle = <0x43>;

				pins_cmd_dat {
					pins = <0xf300>;
					slew-rate = <0x01>;
					output-low;
				};
			};

			chg0_dis_high_cfg {
				linux,phandle = <0x44>;
				phandle = <0x44>;

				pins_cmd_dat {
					pins = <0xf300>;
					slew-rate = <0x01>;
					output-high;
				};
			};

			chg1_dis_low_cfg {
				linux,phandle = <0x45>;
				phandle = <0x45>;

				pins_cmd_dat {
					pins = <0xf200>;
					slew-rate = <0x01>;
					output-low;
				};
			};

			chg1_dis_high_cfg {
				linux,phandle = <0x46>;
				phandle = <0x46>;

				pins_cmd_dat {
					pins = <0xf200>;
					slew-rate = <0x01>;
					output-high;
				};
			};

			usb_typec_default {
				linux,phandle = <0x75>;
				phandle = <0x75>;
			};

			usb_typec_eint_init {
				linux,phandle = <0x76>;
				phandle = <0x76>;

				pins_cmd_dat {
					pins = <0xd200>;
					slew-rate = <0x00>;
					bias-pull-up = <0x00>;
				};
			};

			usb_typec_en_low {
				linux,phandle = <0x77>;
				phandle = <0x77>;

				pins_cmd_dat {
					pins = <0xcd00>;
					slew-rate = <0x01>;
					output-low;
				};
			};

			usb_typec_en_high {
				linux,phandle = <0x78>;
				phandle = <0x78>;

				pins_cmd_dat {
					pins = <0xcd00>;
					slew-rate = <0x01>;
					output-high;
				};
			};

			spi1_gpio_default {
				linux,phandle = <0x49>;
				phandle = <0x49>;
			};

			spi1_cs_set@gpio237 {
				linux,phandle = <0x4a>;
				phandle = <0x4a>;

				pins_cmd_dat {
					pins = <0xed01>;
					input-enable;
				};
			};

			spi1_cs_clear@gpio237 {
				linux,phandle = <0x4b>;
				phandle = <0x4b>;

				pins_cmd_dat {
					pins = <0xed00>;
					slew-rate = <0x00>;
					input-disable;
					bias-disable;
					input-schmitt-enable;
				};
			};

			spi1_clk_set@gpio234 {
				linux,phandle = <0x4c>;
				phandle = <0x4c>;

				pins_cmd_dat {
					pins = <0xea01>;
					input-enable;
				};
			};

			spi1_clk_clear@gpio234 {
				linux,phandle = <0x4d>;
				phandle = <0x4d>;

				pins_cmd_dat {
					pins = <0xea00>;
					slew-rate = <0x00>;
					input-disable;
					bias-disable;
					input-schmitt-enable;
				};
			};

			spi1_miso_set@gpio235 {
				linux,phandle = <0x4e>;
				phandle = <0x4e>;

				pins_cmd_dat {
					pins = <0xeb01>;
					input-enable;
				};
			};

			spi1_miso_clear@gpio235 {
				linux,phandle = <0x4f>;
				phandle = <0x4f>;

				pins_cmd_dat {
					pins = <0xeb00>;
					slew-rate = <0x00>;
					input-disable;
					bias-disable;
					input-schmitt-enable;
				};
			};

			spi1_mosi_set@gpio236 {
				linux,phandle = <0x50>;
				phandle = <0x50>;

				pins_cmd_dat {
					pins = <0xec01>;
					input-enable;
				};
			};

			spi1_mosi_clear@gpio236 {
				linux,phandle = <0x51>;
				phandle = <0x51>;

				pins_cmd_dat {
					pins = <0xec00>;
					slew-rate = <0x00>;
					input-disable;
					bias-disable;
					input-schmitt-enable;
				};
			};

			scp_dvfs_default {
				linux,phandle = <0x35>;
				phandle = <0x35>;
			};

			scp_gpio_off {
				linux,phandle = <0x36>;
				phandle = <0x36>;

				pins_cmd_dat {
					pins = <0x9200>;
				};
			};

			scp_gpio_on {
				linux,phandle = <0x37>;
				phandle = <0x37>;

				pins_cmd_dat {
					pins = <0x9201>;
				};
			};

			low_cfg {
				linux,phandle = <0x56>;
				phandle = <0x56>;

				pins_cmd_dat {
					pins = <0x1d00>;
					slew-rate = <0x01>;
					output-low;
				};
			};

			high_cfg {
				linux,phandle = <0x57>;
				phandle = <0x57>;

				pins_cmd_dat {
					pins = <0x1d00>;
					slew-rate = <0x01>;
					output-high;
				};
			};

			motor_pins_default {
				linux,phandle = <0x55>;
				phandle = <0x55>;
			};

			da9214_gpio_def@gpio61 {
				linux,phandle = <0x93>;
				phandle = <0x93>;

				pins_cmd_dat {
					pins = <0x3d00>;
					slew-rate = <0x00>;
					bias-pull-up = <0x00>;
					input-schmitt-enable = <0x00>;
				};
			};

			set_sim1_gpio_default {
				linux,phandle = <0x90>;
				phandle = <0x90>;
			};

			sim1_gpio_mode {
				linux,phandle = <0x91>;
				phandle = <0x91>;

				pins_cmd_dat {
					pins = <0x7000>;
					slew-rate = <0x00>;
					bias-pull-up = <0x00>;
				};
			};

			sim1_eint_mode {
				linux,phandle = <0x92>;
				phandle = <0x92>;

				pins_cmd_dat {
					pins = <0x7001>;
					slew-rate = <0x00>;
					bias-pull-up = <0x00>;
				};
			};
		};

		sleep@10006000 {
			compatible = "mediatek,sleep";
			reg = <0x10006000 0x1000>;
			interrupts = <0x00 0xb4 0x08>;
		};

		toprgu@10007000 {
			compatible = "mediatek,mt6797-toprgu";
			reg = <0x10007000 0x1000>;
			interrupts = <0x00 0x89 0x02>;
		};

		apxgpt@10008000 {
			compatible = "mediatek,mt6797-apxgpt";
			reg = <0x10008000 0x1000>;
			interrupts = <0x00 0xa9 0x08>;
			clock-frequency = <0xc65d40>;
		};

		timer {
			compatible = "arm,armv8-timer";
			interrupts = <0x01 0x0d 0x08 0x01 0x0e 0x08 0x01 0x0b 0x08 0x01 0x0a 0x08>;
			clock-frequency = <0xc65d40>;
		};

		rsvd@10009000 {
			compatible = "mediatek,rsvd";
			reg = <0x10009000 0x1000>;
		};

		hacc@1000a000 {
			compatible = "mediatek,hacc";
			reg = <0x1000a000 0x1000>;
			interrupts = <0x00 0xc4 0x08>;
		};

		eintc@1000b000 {
			compatible = "mediatek,mt-eic";
			reg = <0x1000b000 0x1000>;
			interrupts = <0x00 0xaa 0x04>;
			#interrupt-cells = <0x02>;
			interrupt-controller;
			mediatek,max_eint_num = <0xc0>;
			mediatek,max_deint_cnt = <0x04>;
			mediatek,deint_possible_irq = <0xce 0xcf 0xd0 0xd1>;
			mediatek,mapping_table_entry = <0xac>;
			mediatek,debtime_setting_entry = <0x0a>;
			mediatek,debtime_setting_array = <0x00 0x80 0x01 0x100 0x02 0x200 0x03 0x400 0x04 0x4000 0x05 0x8000 0x06 0x10000 0x07 0x20000 0x08 0x40000 0x09 0x80000>;
			mediatek,mapping_table = <0x3d 0x00 0x3e 0x01 0x3f 0x02 0x40 0x03 0x41 0x04 0x42 0x05 0x43 0x06 0x44 0x07 0x55 0x08 0x56 0x09 0x57 0x0a 0x58 0x0b 0x59 0x0c 0x5a 0x0d 0x5b 0x0e 0x5c 0x0f 0x5d 0x10 0x1c 0x11 0x1d 0x12 0x1f 0x13 0x20 0x14 0x21 0x15 0x22 0x16 0x23 0x17 0x24 0x18 0x25 0x19 0x26 0x1a 0x27 0x1b 0x28 0x1c 0x29 0x1d 0x2a 0x1e 0x2b 0x1f 0x2c 0x20 0x2d 0x21 0x2e 0x22 0x2f 0x23 0x30 0x24 0x31 0x25 0x32 0x26 0x33 0x27 0x34 0x28 0x35 0x29 0x36 0x2a 0x37 0x2b 0x38 0x2c 0x39 0x2d 0x3a 0x2e 0x3b 0x2f 0x3c 0x30 0x45 0x31 0x46 0x32 0x47 0x33 0x48 0x34 0x49 0x35 0x4a 0x36 0x4b 0x37 0x4c 0x38 0x4d 0x39 0x4e 0x3a 0x4f 0x3b 0x50 0x3c 0x51 0x3d 0x52 0x3e 0x53 0x3f 0x54 0x40 0x5e 0x41 0x5f 0x42 0x60 0x43 0x61 0x44 0x62 0x45 0x6a 0x49 0x6b 0x4a 0x6c 0x4b 0x6d 0x4c 0x6e 0x4d 0x6f 0x4e 0x70 0x4f 0x71 0x50 0x7e 0x51 0x7f 0x52 0x80 0x53 0x81 0x54 0x82 0x55 0x83 0x56 0x84 0x57 0x85 0x58 0x86 0x59 0x87 0x5a 0x88 0x5b 0x89 0x5c 0x8a 0x5d 0x8b 0x5e 0x8c 0x5f 0x8d 0x60 0x97 0x61 0x98 0x62 0x99 0x63 0x9a 0x64 0x9b 0x65 0x9c 0x66 0x9d 0x67 0xb3 0x68 0xb4 0x69 0xb5 0x6a 0xb7 0x6b 0xb8 0x6c 0xb9 0x6d 0xba 0x6e 0xbb 0x6f 0xbc 0x70 0xbd 0x71 0xbe 0x72 0xbf 0x73 0xc0 0x74 0xc1 0x75 0xc2 0x76 0xc3 0x77 0xc4 0x78 0xc5 0x79 0xc6 0x7a 0xc7 0x7b 0xc8 0x7c 0xc9 0x7d 0xca 0x7e 0xcb 0x7f 0xcc 0x80 0xcd 0x81 0xce 0x82 0xcf 0x83 0xd0 0x84 0xd1 0x85 0xd2 0x86 0xd3 0x87 0xd4 0x88 0xd5 0x89 0xd6 0x8a 0xd7 0x8b 0xd8 0x8c 0xd9 0x8d 0xda 0x8e 0xdb 0x8f 0xe8 0x90 0xe9 0x91 0xea 0x92 0xeb 0x93 0xec 0x94 0xed 0x95 0xee 0x96 0xef 0x97 0xf0 0x98 0xf1 0x99 0xf2 0x9a 0xf3 0x9b 0xf4 0x9c 0xf5 0x9d 0xf6 0x9e 0xf7 0x9f 0xf8 0xa0 0xf9 0xa1 0xfa 0xa2 0xfb 0xa3 0xfc 0xa4 0xfd 0xa5 0xfe 0xa6 0xff 0xa7 0x100 0xa8 0x101 0xa9 0x102 0xaa 0x103 0xab 0x104 0xac 0x105 0xad 0x106 0xb0>;
			mediatek,builtin_entry = <0x04>;
			mediatek,builtin_mapping = <0x3d 0x02 0xba 0x5d 0x02 0xba 0x6b 0x02 0xba 0xb5 0x01 0xba>;
			linux,phandle = <0x33>;
			phandle = <0x33>;

			MD1_SIM1_HOT_PLUG_EINT@0 {
				compatible = "mediatek,MD1_SIM1_HOT_PLUG_EINT-eint";
				interrupts = <0x00 0x08>;
				debounce = <0x00 0x186a0>;
				dedicated = <0x00 0x00>;
				src_pin = <0x00 0x01>;
				sockettype = <0x00 0x00>;
				status = "okay";
			};
		};

		apmixed@1000c000 {
			compatible = "mediatek,apmixed";
			reg = <0x1000c000 0x1000>;
			#clock-cells = <0x01>;
			linux,phandle = <0x5a>;
			phandle = <0x5a>;
		};

		fhctl@1000cf00 {
			compatible = "mediatek,fhctl";
			reg = <0x1000cf00 0x100>;
		};

		pwrap@1000d000 {
			compatible = "mediatek,pwrap";
			reg = <0x1000d000 0x1000>;
			interrupts = <0x00 0xb2 0x04>;

			mt6351 {
				compatible = "mediatek,mt6351-pmic";
				interrupt-parent = <0x33>;
				interrupts = <0x106 0x04>;
				debounce = <0x106 0x3e8>;
				interrupt-controller;
			};
		};

		devapc_ao@1000e000 {
			compatible = "mediatek,devapc_ao";
			reg = <0x1000e000 0x1000>;
		};

		ddrphy@1000f000 {
			compatible = "mediatek,ddrphy";
			reg = <0x1000f000 0x1000>;
		};

		keypad@10010000 {
			compatible = "mediatek,mt6797-keypad";
			reg = <0x10010000 0x1000>;
			interrupts = <0x00 0xb3 0x02>;
			mediatek,kpd-key-debounce = <0x400>;
			mediatek,kpd-sw-pwrkey = <0x74>;
			mediatek,kpd-hw-pwrkey = <0x08>;
			mediatek,kpd-sw-rstkey = <0x66>;
			mediatek,kpd-hw-rstkey = <0x11>;
			mediatek,kpd-use-extend-type = <0x00>;
			mediatek,kpd-hw-map-num = <0x48>;
			mediatek,kpd-hw-init-map = <0x72 0x73 0x00 0x00 0x00 0x00 0x00 0x00 0x00 0x00 0x00 0x00 0x00 0x00 0x00 0x00 0x00 0x00 0x00 0x00 0x00 0x00 0x00 0x00 0x00 0x00 0x00 0x00 0x00 0x00 0x00 0x00 0x00 0x00 0x00 0x00 0x00 0x00 0x00 0x00 0x00 0x00 0x00 0x00 0x00 0x00 0x00 0x00 0x00 0x00 0x00 0x00 0x00 0x00 0x00 0x00 0x00 0x00 0x00 0x00 0x00 0x00 0x00 0x00 0x00 0x00 0x00 0x00 0x00 0x00 0x00 0x00>;
			mediatek,kpd-pwrkey-eint-gpio = <0x00>;
			mediatek,kpd-pwkey-gpio-din = <0x00>;
			mediatek,kpd-hw-recovery-key = <0x01>;
			mediatek,kpd-hw-factory-key = <0x00>;
			status = "okay";
		};

		bq27532_int@0 {
			compatible = "mediatek,bq27532_int-eint";
			interrupt-parent = <0x33>;
			interrupts = <0x3e 0x02>;
			debounce = <0x3e 0x00>;
			status = "okay";
		};

		bat_metter {
			compatible = "mediatek,bat_meter";
			stop_charging_in_takling = <0x01>;
			talking_recharge_voltage = <0xed8>;
			talking_sync_time = <0x3c>;
			mtk_temperature_recharge_support = <0x01>;
			max_charge_temperature = <0x32>;
			max_charge_temperature_minus_x_degree = <0x2f>;
			min_charge_temperature = <0x00>;
			min_charge_temperature_plus_x_degree = <0x06>;
			err_charge_temperature = <0xff>;
			v_pre2cc_thres = <0xd48>;
			v_cc2topoff_thres = <0xfd2>;
			recharging_voltage = <0x100e>;
			charging_full_current = <0x64>;
			config_usb_if = <0x00>;
			usb_charger_current_suspend = <0x00>;
			usb_charger_current_unconfigured = <0x1b58>;
			usb_charger_current_configured = <0xc350>;
			usb_charger_current = <0xc350>;
			ac_charger_current = <0x13880>;
			non_std_ac_charger_current = <0xc350>;
			charging_host_charger_current = <0xfde8>;
			apple_0_5a_charger_current = <0xc350>;
			apple_1_0a_charger_current = <0xfde8>;
			apple_2_1a_charger_current = <0x13880>;
			bat_low_temp_protect_enable = <0x00>;
			v_charger_enable = <0x00>;
			v_charger_max = <0x1964>;
			v_charger_min = <0x1130>;
			onehundred_percent_tracking_time = <0x0a>;
			npercent_tracking_time = <0x14>;
			sync_to_real_tracking_time = <0x3c>;
			v_0percent_tracking = <0xd7a>;
			high_battery_voltage_support = <0x00>;
			r_bat_sense = <0x04>;
			r_i_sense = <0x04>;
			r_charger_1 = <0x14a>;
			r_charger_2 = <0x27>;
			temperature_t0 = <0x6e>;
			temperature_t1 = <0x00>;
			temperature_t2 = <0x19>;
			temperature_t3 = <0x32>;
			temperature_t = <0xff>;
			fg_meter_resistance = <0x00>;
			q_max_pos_50 = <0xab7>;
			q_max_pos_25 = <0xa93>;
			q_max_pos_0 = <0x348>;
			q_max_neg_10 = <0x327>;
			q_max_pos_50_h_current = <0xa80>;
			q_max_pos_25_h_current = <0xa5d>;
			q_max_pos_0_h_current = <0x337>;
			q_max_neg_10_h_current = <0x317>;
			oam_d5 = <0x01>;
			change_tracking_point = <0x01>;
			cust_tracking_point = <0x00>;
			cust_r_sense = <0x38>;
			cust_hw_cc = <0x00>;
			aging_tuning_value = <0x67>;
			cust_r_fg_offset = <0x00>;
			ocv_board_compesate = <0x00>;
			r_fg_board_base = <0x3e8>;
			r_fg_board_slope = <0x3e8>;
			car_tune_value = <0x76>;
			current_detect_r_fg = <0x0a>;
			minerroroffset = <0x3e8>;
			fg_vbat_average_size = <0x12>;
			r_fg_value = <0x0a>;
			difference_hwocv_rtc = <0x1e>;
			difference_hwocv_swocv = <0x0a>;
			difference_swocv_rtc = <0x0a>;
			max_swocv = <0x03>;
			difference_voltage_update = <0x14>;
			aging1_load_soc = <0x46>;
			aging1_update_soc = <0x1e>;
			batterypseudo100 = <0x5f>;
			batterypseudo1 = <0x0b>;
			q_max_by_sys = <0x01>;
			q_max_sys_voltage = <0xd16>;
			shutdown_gauge0 = <0x01>;
			shutdown_gauge1_xmins = <0x01>;
			shutdown_gauge1_mins = <0x3c>;
			shutdown_system_voltage = <0xd48>;
			charge_tracking_time = <0x3c>;
			discharge_tracking_time = <0x0a>;
			recharge_tolerance = <0x0a>;
			sync_ui_soc_imm = <0x00>;
			mtk_enable_aging_algorithm = <0x01>;
			md_sleep_current_check = <0x01>;
			q_max_by_current = <0x00>;
			cust_poweron_delta_capacity_tolrance = <0x28>;
			cust_poweron_low_capacity_tolrance = <0x05>;
			cust_poweron_max_vbat_tolrance = <0x5a>;
			cust_poweron_delta_vbat_tolrance = <0x1e>;
			cust_poweron_delta_hw_sw_ocv_capacity_tolrance = <0x0a>;
			fixed_tbat_25 = <0x00>;
			vbat_normal_wakeup = <0xe10>;
			vbat_low_power_wakeup = <0xdac>;
			normal_wakeup_period = <0x1518>;
			low_power_wakeup_period = <0x12c>;
			close_poweroff_wakeup_period = <0x1e>;
			rbat_pull_up_r = <0x5dc0>;
			rbat_pull_up_volt = <0x708>;
			batt_temperature_table_num = <0x11>;
			batt_temperature_table = <0xffffffec 0x10a8d 0xfffffff1 0xd192 0xfffffff6 0xa60a 0xfffffffb 0x8464 0x00 0x6a53 0x05 0x5605 0x0a 0x4606 0x0f 0x3952 0x14 0x2f31 0x19 0x2710 0x1e 0x207b 0x23 0x1b24 0x28 0x16ca 0x2d 0x1335 0x32 0x1041 0x37 0xdcf 0x3c 0xbc6>;
			battery_profile_t0_num = <0x52>;
			battery_profile_t0 = <0x00 0x10cf 0x06 0x10b9 0x0d 0x10a5 0x12 0x1090 0x19 0x1079 0x1f 0x1062 0x26 0x1049 0x2c 0x1031 0x33 0x1015 0x38 0xff8 0x3e 0xfe4 0x45 0xfcf 0x4b 0xfb3 0x52 0xf9d 0x57 0xf8d 0x5e 0xf7f 0x64 0xf74 0x6b 0xf66 0x71 0xf59 0x76 0xf49 0x7d 0xf37 0x80 0xf28 0x87 0xf1d 0x8d 0xf11 0x93 0xf08 0x9a 0xeff 0x9f 0xef6 0xa6 0xeef 0xac 0xeea 0xb3 0xee3 0xb9 0xede 0xc0 0xed8 0xc5 0xed4 0xcb 0xecf 0xd2 0xecb 0xd8 0xec5 0xdf 0xebf 0xe4 0xeba 0xeb 0xeb0 0xf1 0xea8 0xf8 0xe9e 0xfe 0xe93 0x103 0xe89 0x10a 0xe81 0x110 0xe78 0x117 0xe72 0x11d 0xe68 0x124 0xe51 0x129 0xe1d 0x130 0xdc6 0x133 0xd8a 0x136 0xd74 0x139 0xd60 0x139 0xd4c>;
			battery_profile_t1_num = <0x52>;
			battery_profile_t1 = <0x00 0x10dc 0x07 0x10bb 0x0c 0x1094 0x14 0x1072 0x16 0x1059 0x1d 0x1044 0x22 0x1030 0x29 0x1020 0x31 0x100d 0x36 0xffd 0x3d 0xff0 0x3f 0xfe5 0x47 0xfcf 0x4e 0xfb7 0x53 0xfa3 0x5a 0xf95 0x5f 0xf89 0x64 0xf7f 0x69 0xf73 0x70 0xf64 0x78 0xf53 0x7c 0xf43 0x84 0xf33 0x8b 0xf25 0x8d 0xf18 0x95 0xf0f 0x9a 0xf06 0xa1 0xefd 0xa6 0xef7 0xad 0xeef 0xb5 0xee7 0xb7 0xee3 0xbe 0xedc 0xc3 0xed7 0xca 0xed2 0xd2 0xece 0xd7 0xec9 0xde 0xec6 0xe0 0xec2 0xe8 0xebd 0xed 0xeb8 0xf4 0xeb1 0xfb 0xea9 0x100 0xe9e 0x105 0xe8f 0x10a 0xe80 0x111 0xe78 0x116 0xe75 0x11d 0xe72 0x125 0xe6c 0x12a 0xe60 0x12e 0xe29 0x133 0xdc8 0x13b 0xd90 0x142 0xd4b 0x144 0xcfb 0x144 0xcc3 0x144 0xc9e 0x147 0xc83 0x147 0xc6c 0x147 0xc55 0x147 0xc45 0x147 0xc34 0x147 0xc25 0x147 0xc18 0x147 0xc0c 0x147 0xc07 0x147 0xbfb 0x147 0xbf2 0x147 0xbe7 0x147 0xbe1 0x147 0xbd8 0x147 0xbd5 0x147 0xbca 0x147 0xbc0 0x147 0xbba 0x147 0xbbb 0x147 0xbb3 0x147 0xba9 0x147 0xba7 0x147 0xba3 0x147 0xb97>;
			battery_profile_t2_num = <0x52>;
			battery_profile_t2 = <0x00 0x10e8 0x02 0x10cf 0x04 0x10bb 0x05 0x10a7 0x07 0x1095 0x09 0x1083 0x0b 0x1071 0x0d 0x105d 0x0e 0x104d 0x10 0x103b 0x13 0x102a 0x15 0x1019 0x16 0x1008 0x18 0xff7 0x1a 0xfe8 0x1c 0xfda 0x1e 0xfc9 0x1f 0xfb9 0x21 0xfab 0x23 0xf9c 0x25 0xf8f 0x27 0xf84 0x28 0xf76 0x2a 0xf69 0x2c 0xf56 0x2e 0xf43 0x30 0xf31 0x31 0xf24 0x34 0xf19 0x36 0xf0e 0x38 0xf06 0x39 0xf00 0x3b 0xef8 0x3d 0xef0 0x3f 0xeea 0x41 0xee5 0x42 0xedd 0x44 0xed9 0x46 0xed2 0x48 0xecd 0x4a 0xec8 0x4b 0xec2 0x4d 0xebc 0x4f 0xeb5 0x51 0xea9 0x54 0xea1 0x55 0xe95 0x57 0xe85 0x59 0xe73 0x5b 0xe6c 0x5c 0xe6b 0x5e 0xe69 0x60 0xe67 0x62 0xe54 0x64 0xe0d 0x65 0xda9 0x67 0xd3f 0x68 0xc55 0x69 0xc01 0x69 0xbce 0x69 0xbb0 0x69 0xb99 0x69 0xb8e 0x69 0xb82 0x69 0xb76 0x69 0xb6d 0x69 0xb61 0x69 0xb5e 0x69 0xb54 0x69 0xb4b 0x69 0xb4b 0x69 0xb4b 0x69 0xb4b 0x69 0xb4b 0x69 0xb4b 0x69 0xb4b 0x69 0xb4b 0x69 0xb4b 0x69 0xb4b 0x69 0xb4b 0x69 0xb4b 0x69 0xb4b>;
			battery_profile_t3_num = <0x52>;
			battery_profile_t3 = <0x00 0x10eb 0x02 0x10d1 0x03 0x10bc 0x05 0x10a9 0x07 0x1094 0x0a 0x1081 0x0b 0x106e 0x0d 0x105c 0x0f 0x104a 0x10 0x1039 0x12 0x1027 0x14 0x1017 0x16 0x1006 0x17 0xff5 0x1a 0xfe5 0x1c 0xfd6 0x1d 0xfc6 0x1f 0xfb7 0x21 0xfaa 0x23 0xf9c 0x24 0xf90 0x26 0xf82 0x28 0xf76 0x29 0xf6b 0x2c 0xf5e 0x2e 0xf51 0x2f 0xf40 0x31 0xf2c 0x33 0xf1c 0x35 0xf11 0x36 0xf08 0x38 0xefe 0x3b 0xef8 0x3c 0xef0 0x3e 0xee9 0x40 0xee3 0x42 0xede 0x43 0xed8 0x45 0xed2 0x47 0xece 0x48 0xec8 0x4a 0xec1 0x4d 0xeb3 0x4f 0xeae 0x50 0xea6 0x52 0xe9e 0x54 0xe95 0x55 0xe8b 0x57 0xe7d 0x59 0xe6e 0x5b 0xe5e 0x5d 0xe5c 0x5f 0xe5b 0x61 0xe5a 0x62 0xe55 0x64 0xe29 0x66 0xddb 0x68 0xda7 0x69 0xd82 0x6b 0xd03 0x6d 0xc44 0x6d 0xc06 0x6d 0xbd9 0x6d 0xbb9 0x6d 0xba4 0x6e 0xb90 0x6e 0xb80 0x6e 0xb74 0x6e 0xb69 0x6e 0xb61 0x6e 0xb57 0x6e 0xb53 0x6e 0xb49 0x6e 0xb49 0x6e 0xb49 0x6e 0xb49 0x6e 0xb49 0x6e 0xb49 0x6e 0xb49 0x6e 0xb49 0x6e 0xb49 0x6e 0xb49>;
			r_profile_t0_num = <0x52>;
			r_profile_t0 = <0x198 0x10cf 0x198 0x10b9 0x19f 0x10a5 0x1a9 0x1090 0x1ae 0x1079 0x1b8 0x1062 0x1cf 0x1049 0x1ea 0x1031 0x20d 0x1015 0x23d 0xff8 0x267 0xfe4 0x28a 0xfcf 0x2a3 0xfb3 0x2ad 0xf9d 0x2c1 0xf8d 0x2c9 0xf7f 0x2d0 0xf74 0x2dd 0xf66 0x2d8 0xf59 0x2e2 0xf49 0x2d5 0xf37 0x2df 0xf28 0x2e9 0xf1d 0x2ec 0xf11 0x2f8 0xf08 0x305 0xeff 0x30f 0xef6 0x323 0xeef 0x334 0xeea 0x343 0xee3 0x35f 0xede 0x378 0xed8 0x387 0xed4 0x39d 0xecf 0x3bb 0xecb 0x3cf 0xec5 0x3e8 0xebf 0x40b 0xeba 0x422 0xeb0 0x442 0xea8 0x451 0xe9e 0x46f 0xe93 0x490 0xe89 0x4ba 0xe81 0x4e7 0xe78 0x541 0xe72 0x596 0xe68 0x5ee 0xe51 0x622 0xe1d 0x652 0xdc6 0x684 0xd8a 0x64d 0xd74 0x61b 0xd60 0x5e6 0xd4c 0x5b4 0xd35 0x578 0xd1d 0x535 0xd04 0x503 0xcee 0x4d1 0xcdb 0x4ae 0xcca 0x483 0xcbb 0x468 0xcad 0x445 0xca2 0x433 0xc95 0x41d 0xc8c 0x3ff 0xc84 0x3fa 0xc79 0x3ed 0xc72 0x3d2 0xc6b 0x3c0 0xc60 0x3ac 0xc5a 0x37f 0xc55 0x37a 0xc4f 0x35f 0xc47 0x39d 0xc3d 0x37d 0xc35 0x37d 0xc35 0x37d 0xc35 0x37d 0xc35 0x37d 0xc35 0x37d 0xc35 0x37d 0xc35>;
			r_profile_t1_num = <0x52>;
			r_profile_t1 = <0x102 0x10dc 0x102 0x10bb 0x116 0x1094 0x12f 0x1072 0x14d 0x1059 0x157 0x1044 0x15e 0x1030 0x16d 0x1020 0x172 0x100d 0x172 0xffd 0x17c 0xff0 0x193 0xfe5 0x18b 0xfcf 0x193 0xfb7 0x193 0xfa3 0x19d 0xf95 0x1a2 0xf89 0x1a4 0xf7f 0x1a7 0xf73 0x19f 0xf64 0x19a 0xf53 0x190 0xf43 0x189 0xf33 0x189 0xf25 0x184 0xf18 0x18b 0xf0f 0x193 0xf06 0x195 0xefd 0x19f 0xef7 0x1a9 0xeef 0x1ae 0xee7 0x1bb 0xee3 0x1c2 0xedc 0x1d1 0xed7 0x1db 0xed2 0x1e3 0xece 0x1ea 0xec9 0x1f7 0xec6 0x208 0xec2 0x215 0xebd 0x221 0xeb8 0x233 0xeb1 0x24c 0xea9 0x258 0xe9e 0x260 0xe8f 0x267 0xe80 0x27b 0xe78 0x29e 0xe75 0x2c6 0xe72 0x2fd 0xe6c 0x348 0xe60 0x370 0xe29 0x393 0xdc8 0x438 0xd90 0x52b 0xd4b 0x523 0xcfb 0x49c 0xcc3 0x438 0xc9e 0x3f2 0xc83 0x3be 0xc6c 0x39d 0xc55 0x378 0xc45 0x35c 0xc34 0x32a 0xc25 0x314 0xc18 0x2fd 0xc0c 0x2bc 0xc07 0x2e9 0xbfb 0x2a8 0xbf2 0x2ad 0xbe7 0x28a 0xbe1 0x2ab 0xbd8 0x267 0xbd5 0x283 0xbca 0x294 0xbc0 0x27b 0xbba 0x212 0xbbb 0x280 0xbb3 0x253 0xba9 0x217 0xba7 0x1cf 0xba3 0x258 0xb97>;
			r_profile_t2_num = <0x52>;
			r_profile_t2 = <0x9b 0x10e8 0x9b 0x10cf 0x9b 0x10bb 0x9e 0x10a7 0x9e 0x1095 0xa3 0x1083 0xa5 0x1071 0xa5 0x105d 0xaa 0x104d 0xaa 0x103b 0xad 0x102a 0xad 0x1019 0xad 0x1008 0xb2 0xff7 0xb4 0xfe8 0xb9 0xfda 0xbc 0xfc9 0xbe 0xfb9 0xc8 0xfab 0xc8 0xf9c 0xcd 0xf8f 0xda 0xf84 0xd7 0xf76 0xd7 0xf69 0xc8 0xf56 0xbc 0xf43 0xad 0xf31 0xa8 0xf24 0xa3 0xf19 0xa0 0xf0e 0xa3 0xf06 0xa8 0xf00 0xaa 0xef8 0xaa 0xef0 0xaa 0xeea 0xb2 0xee5 0xaf 0xedd 0xb7 0xed9 0xb4 0xed2 0xb7 0xecd 0xb9 0xec8 0xb7 0xec2 0xb9 0xebc 0xb7 0xeb5 0xad 0xea9 0xad 0xea1 0xad 0xe95 0xad 0xe85 0xad 0xe73 0xaa 0xe6c 0xaf 0xe6b 0xb9 0xe69 0xc6 0xe67 0xcd 0xe54 0xd0 0xe0d 0xf0 0xda9 0x111 0xd3f 0x38c 0xc55 0x2c1 0xc01 0x253 0xbce 0x201 0xbb0 0x1d1 0xb99 0x19d 0xb8e 0x17c 0xb82 0x170 0xb76 0x168 0xb6d 0x14f 0xb61 0x113 0xb5e 0x13b 0xb54 0x11b 0xb4b 0x11b 0xb4b 0x11b 0xb4b 0x11b 0xb4b 0x11b 0xb4b 0x11b 0xb4b 0x11b 0xb4b 0x11b 0xb4b 0x11b 0xb4b 0x11b 0xb4b 0x11b 0xb4b 0x11b 0xb4b 0x11b 0xb4b>;
			r_profile_t3_num = <0x52>;
			r_profile_t3 = <0x7b 0x10eb 0x7b 0x10d1 0x80 0x10bc 0x82 0x10a9 0x82 0x1094 0x82 0x1081 0x80 0x106e 0x7d 0x105c 0x82 0x104a 0x85 0x1039 0x85 0x1027 0x8a 0x1017 0x8a 0x1006 0x8c 0xff5 0x8c 0xfe5 0x8f 0xfd6 0x8c 0xfc6 0x8f 0xfb7 0x94 0xfaa 0x99 0xf9c 0x9b 0xf90 0x9b 0xf82 0xa5 0xf76 0xaf 0xf6b 0xaf 0xf5e 0xb2 0xf51 0xaa 0xf40 0x94 0xf2c 0x87 0xf1c 0x87 0xf11 0x85 0xf08 0x85 0xefe 0x87 0xef8 0x87 0xef0 0x87 0xee9 0x8f 0xee3 0x91 0xede 0x94 0xed8 0x91 0xed2 0x99 0xece 0x96 0xec8 0x96 0xec1 0x85 0xeb3 0x8f 0xeae 0x8c 0xea6 0x8a 0xe9e 0x87 0xe95 0x87 0xe8b 0x85 0xe7d 0x85 0xe6e 0x82 0xe5e 0x82 0xe5c 0x8a 0xe5b 0x94 0xe5a 0xa0 0xe55 0x9e 0xe29 0xaa 0xddb 0xd0 0xda7 0xdc 0xd82 0x109 0xd03 0x357 0xc44 0x2d5 0xc06 0x258 0xbd9 0x210 0xbb9 0x1cc 0xba4 0x190 0xb90 0x17c 0xb80 0x163 0xb74 0x13b 0xb69 0x12f 0xb61 0x134 0xb57 0xff 0xb53 0x111 0xb49 0x111 0xb49 0x111 0xb49 0x111 0xb49 0x111 0xb49 0x111 0xb49 0x111 0xb49 0x111 0xb49 0x111 0xb49 0x111 0xb49>;
		};

		topmisc@10011000 {
			compatible = "mediatek,topmisc";
			reg = <0x10011000 0x1000>;
		};

		ddrphy_b@10012000 {
			compatible = "mediatek,ddrphy_b";
			reg = <0x10012000 0x1000>;
		};

		dramc_conf_b@10013000 {
			compatible = "mediatek,dramc_conf_b";
			reg = <0x10013000 0x1000>;
		};

		mdcldma@10014000 {
			compatible = "mediatek,mdcldma";
			reg = <0x10014000 0x1e00 0x10015000 0x1e00 0x10219000 0x1e00 0x1021a000 0x1e00 0x10209000 0x1000 0x1020a000 0x1000>;
			interrupts = <0x00 0x109 0x04 0x00 0x93 0x08 0x00 0x10a 0x02>;
			mediatek,md_id = <0x00>;
			mediatek,cldma_capability = <0x06>;
			mediatek,md_smem_size = <0x100000>;
			clocks = <0x34 0x01 0x02 0x31 0x02 0x33 0x02 0x2a 0x02 0x2b 0x02 0x1a 0x02 0x1b 0x02 0x1c 0x02 0x1f 0x02 0x22 0x02 0x25>;
			clock-names = "scp-sys-md1-main\0infra-ccif-ap\0infra-ccif-md\0infra-ap-c2k-ccif-0\0infra-ap-c2k-ccif-1\0infra-md2md-ccif-0\0infra-md2md-ccif-1\0infra-md2md-ccif-2\0infra-md2md-ccif-3\0infra-md2md-ccif-4\0infra-md2md-ccif-5";
		};

		aes_top0@10016000 {
			compatible = "mediatek,aes_top0";
			reg = <0x10016000 0x1000>;
		};

		aes_top1@10017000 {
			compatible = "mediatek,aes_top1";
			reg = <0x10017000 0x1000>;
		};

		ddrphy_c@10018000 {
			compatible = "mediatek,ddrphy_c";
			reg = <0x10018000 0x1000>;
		};

		ddrphy_d@10019000 {
			compatible = "mediatek,ddrphy_d";
			reg = <0x10019000 0x1000>;
		};

		mcumixed@1001a000 {
			compatible = "mediatek,mcumixed";
			reg = <0x1001a000 0x1000>;
		};

		mcufhctl@1001af00 {
			compatible = "mediatek,mcufhctl";
			reg = <0x1001af00 0x100>;
		};

		c2kmisc@1001b000 {
			compatible = "mediatek,c2kmisc";
			reg = <0x1001b000 0x1000>;
		};

		modem_temp@1001c000 {
			compatible = "mediatek,modem_temp";
			reg = <0x1001c000 0x1000>;
		};

		scp@10020000 {
			compatible = "mediatek,scp";
			status = "disabled";
			reg = <0x10020000 0x80000 0x100a0000 0x1000 0x100a4000 0x1000>;
			interrupts = <0x00 0xc7 0x04>;
		};

		scpdvfs@0 {
			compatible = "mediatek,mt6797-scpdvfs";
			pinctrl-names = "default\0scp_gpio_off\0scp_gpio_on";
			pinctrl-0 = <0x35>;
			pinctrl-1 = <0x36>;
			pinctrl-2 = <0x37>;
			status = "okay";
		};

		emi_mpu@10200000 {
			compatible = "mediatek,emi_mpu";
			reg = <0x10200000 0x1000>;
		};

		infracfg@10201000 {
			compatible = "mediatek,infracfg";
			reg = <0x10201000 0x1000>;
		};

		sramrom@10202000 {
			compatible = "mediatek,sramrom";
			reg = <0x10202000 0x1000>;
		};

		emi@10203000 {
			compatible = "mediatek,emi";
			reg = <0x10203000 0x1000>;
			interrupts = <0x00 0x8f 0x08>;
		};

		sys_cirq@10204000 {
			compatible = "mediatek,mt6797-sys_cirq\0mediatek,mt6735-sys_cirq";
			reg = <0x10204000 0x1000>;
			interrupts = <0x00 0x123 0x08>;
			mediatek,cirq_num = <0xdc>;
			mediatek,spi_start_offset = <0x48>;
		};

		m4u@10205000 {
			cell-index = <0x00>;
			compatible = "mediatek,m4u";
			reg = <0x10205000 0x1000>;
			interrupts = <0x00 0x9c 0x08>;
			clocks = <0x38 0x01 0x38 0x02 0x39 0x03 0x39 0x04 0x3a 0x07 0x3b 0x02 0x3c 0x01 0x3c 0x06 0x38 0x03 0x3d 0x04 0x34 0x03 0x34 0x05 0x34 0x0d 0x34 0x0c 0x34 0x04>;
			clock-names = "m4u_mm_smi_common\0m4u_mm_smi_larb0\0m4u_vdec_cken\0m4u_vdec_larb1_cken\0m4u_cam_larb2\0m4u_venc_1\0m4u_mjc_smi_larb\0m4u_mjc_larb4_asif\0m4u_mm_smi_larb5\0m4u_img_larb6\0m4u_mtcmos_dis\0m4u_mtcmos_vde\0m4u_mtcmos_ven\0m4u_mtcmos_mjc\0m4u_mtcmos_isp";
		};

		efusec@10206000 {
			compatible = "mediatek,efusec";
			reg = <0x10206000 0x1000>;
		};

		devapc@10207000 {
			compatible = "mediatek,devapc";
			reg = <0x10207000 0x1000>;
			interrupts = <0x00 0x8d 0x08>;
		};

		bus_dbg@10208000 {
			compatible = "mediatek,bus_dbg-v2";
			reg = <0x10208000 0x1000>;
			interrupts = <0x00 0x8c 0x08>;
		};

		ap_ccif0@10209000 {
			compatible = "mediatek,ap_ccif0";
			reg = <0x10209000 0x1000>;
			interrupts = <0x00 0x93 0x08>;
		};

		md_ccif0@1020a000 {
			compatible = "mediatek,md_ccif0";
			reg = <0x1020a000 0x1000>;
		};

		ap_ccif1@1020b000 {
			compatible = "mediatek,ap_ccif1";
			reg = <0x1020b000 0x1000>;
			interrupts = <0x00 0x95 0x08>;
		};

		ap2c2k_ccif@1020b000 {
			compatible = "mediatek,ap2c2k_ccif";
			reg = <0x1020b000 0x1000 0x10211000 0x300 0x10213000 0x300>;
			interrupts = <0x00 0x95 0x08 0x00 0x11f 0x02>;
			cell-index = <0x02>;
			ccif,major = <0xa9>;
			ccif,minor_base = <0x00>;
			ccif,capability = <0x00>;
			mediatek,md_smem_size = <0x400000>;
			clocks = <0x34 0x0f>;
			clock-names = "scp-sys-c2k-main";
		};

		md_ccif1@1020c000 {
			compatible = "mediatek,md_ccif1";
			reg = <0x1020c000 0x1000>;
		};

		infra_mbist@1020d000 {
			compatible = "mediatek,infra_mbist";
			reg = <0x1020d000 0x1000>;
		};

		dramc_nao@1020e000 {
			compatible = "mediatek,dramc_nao";
			reg = <0x1020e000 0x1000>;
			interrupts = <0x00 0x9e 0x02>;
		};

		trng@1020f000 {
			compatible = "mediatek,trng";
			reg = <0x1020f000 0x1000>;
			interrupts = <0x00 0x94 0x08>;
		};

		gcpu@10210000 {
			compatible = "mediatek,gcpu";
			reg = <0x10210000 0x1000>;
			interrupts = <0x00 0x9f 0x08>;
		};

		md2md_md1_ccif0@10211000 {
			compatible = "mediatek,md2md_md1_ccif0";
			reg = <0x10211000 0x1000>;
		};

		gce@10212000 {
			compatible = "mediatek,gce";
			reg = <0x10212000 0x1000>;
			interrupts = <0x00 0x98 0x08 0x00 0x99 0x08>;
			disp_mutex_reg = <0x1401f000 0x1000>;
			g3d_config_base = <0x13000000 0x00 0xffff0000>;
			mmsys_config_base = <0x14000000 0x01 0xffff0000>;
			disp_dither_base = <0x14010000 0x02 0xffff0000>;
			mm_na_base = <0x14020000 0x03 0xffff0000>;
			imgsys_base = <0x15000000 0x04 0xffff0000>;
			vdec_gcon_base = <0x16000000 0x05 0xffff0000>;
			venc_gcon_base = <0x17000000 0x06 0xffff0000>;
			conn_peri_base = <0x18000000 0x07 0xffff0000>;
			topckgen_base = <0x10000000 0x08 0xffff0000>;
			kp_base = <0x10010000 0x09 0xffff0000>;
			scp_sram_base = <0x10020000 0x0a 0xffff0000>;
			infra_na3_base = <0x10030000 0x0b 0xffff0000>;
			infra_na4_base = <0x10040000 0x0c 0xffff0000>;
			scp_base = <0x10050000 0x0d 0xffff0000>;
			mcucfg_base = <0x10200000 0x0e 0xffff0000>;
			gcpu_base = <0x10210000 0x0f 0xffff0000>;
			usb0_base = <0x11200000 0x10 0xffff0000>;
			usb_sif_base = <0x11210000 0x11 0xffff0000>;
			audio_base = <0x11220000 0x12 0xffff0000>;
			msdc0_base = <0x11230000 0x13 0xffff0000>;
			msdc1_base = <0x11240000 0x14 0xffff0000>;
			msdc2_base = <0x11250000 0x15 0xffff0000>;
			msdc3_base = <0x11260000 0x16 0xffff0000>;
			ap_dma_base = <0x11000000 0x17 0xffff0000>;
			camsys_base = <0x1a000000 0x18 0xffff0000>;
			dip_a0_sw_base = <0x15020000 0x63 0xffff0000>;
			mdp_rdma0_sof = <0x00>;
			mdp_rdma1_sof = <0x01>;
			mdp_rsz0_sof = <0x02>;
			mdp_rsz1_sof = <0x03>;
			mdp_rsz2_sof = <0x04>;
			mdp_tdshp_sof = <0x05>;
			mdp_color_sof = <0x06>;
			mdp_wdma_sof = <0x07>;
			mdp_wrot0_sof = <0x08>;
			mdp_wrot1_sof = <0x09>;
			disp_ovl0_sof = <0x0a>;
			disp_ovl1_sof = <0x0b>;
			disp_2l_ovl0_sof = <0x0c>;
			disp_2l_ovl1_sof = <0x0f>;
			disp_rdma0_sof = <0x0d>;
			disp_rdma1_sof = <0x0e>;
			disp_wdma0_sof = <0x10>;
			disp_wdma1_sof = <0x11>;
			disp_color_sof = <0x12>;
			disp_ccorr_sof = <0x13>;
			disp_aal_sof = <0x14>;
			disp_gamma_sof = <0x15>;
			disp_od_sof = <0x16>;
			disp_dither_sof = <0x17>;
			disp_ufoe_sof = <0x18>;
			disp_dsc_sof = <0x19>;
			disp_pwm0_sof = <0x1a>;
			mdp_rdma0_frame_done = <0x1b>;
			mdp_rdma1_frame_done = <0x1c>;
			mdp_rsz0_frame_done = <0x1d>;
			mdp_rsz1_frame_done = <0x1e>;
			mdp_rsz2_frame_done = <0x1f>;
			mdp_tdshp_frame_done = <0x20>;
			mdp_color_frame_done = <0x21>;
			mdp_wdma_frame_done = <0x22>;
			mdp_wrot0_write_frame_done = <0x23>;
			mdp_wrot0_read_frame_done = <0x24>;
			mdp_wrot1_write_frame_done = <0x25>;
			mdp_wrot1_read_frame_done = <0x26>;
			disp_ovl0_frame_done = <0x27>;
			disp_ovl1_frame_done = <0x28>;
			disp_2l_ovl0_frame_done = <0x29>;
			disp_2l_ovl1_frame_done = <0x2a>;
			disp_rdma0_frame_done = <0x2b>;
			disp_rdma1_frame_done = <0x2c>;
			disp_wdma0_frame_done = <0x2d>;
			disp_wdma1_frame_done = <0x2e>;
			disp_color_frame_done = <0x2f>;
			disp_ccorr_frame_done = <0x30>;
			disp_aal_frame_done = <0x31>;
			disp_gamma_frame_done = <0x32>;
			disp_od_frame_done = <0x33>;
			disp_dither_frame_done = <0x34>;
			disp_ufoe_frame_done = <0x35>;
			disp_dsc_frame_done = <0x36>;
			disp_dsi0_frame_done = <0x37>;
			disp_dsi1_frame_done = <0x38>;
			disp_dpi0_frame_done = <0x39>;
			stream_done_0 = <0x3a>;
			stream_done_1 = <0x3b>;
			stream_done_2 = <0x3c>;
			stream_done_3 = <0x3d>;
			stream_done_4 = <0x3e>;
			stream_done_5 = <0x3f>;
			stream_done_6 = <0x40>;
			stream_done_7 = <0x41>;
			stream_done_8 = <0x42>;
			stream_done_9 = <0x43>;
			buf_underrun_event_0 = <0x44>;
			buf_underrun_event_1 = <0x45>;
			dsi0_te_event = <0x46>;
			dsi1_te_event = <0x47>;
			dip_cq_thread0_frame_done = <0x81>;
			dip_cq_thread1_frame_done = <0x82>;
			dip_cq_thread2_frame_done = <0x83>;
			dip_cq_thread3_frame_done = <0x84>;
			dip_cq_thread4_frame_done = <0x85>;
			dip_cq_thread5_frame_done = <0x86>;
			dip_cq_thread6_frame_done = <0x87>;
			dip_cq_thread7_frame_done = <0x88>;
			dip_cq_thread8_frame_done = <0x89>;
			dip_cq_thread9_frame_done = <0x8a>;
			dip_cq_thread10_frame_done = <0x8b>;
			dip_cq_thread11_frame_done = <0x8c>;
			dip_cq_thread12_frame_done = <0x8d>;
			dip_cq_thread13_frame_done = <0x8e>;
			dip_cq_thread14_frame_done = <0x8f>;
			dpe_frame_done = <0x90>;
			wmf_frame_done = <0x91>;
			venc_done = <0x101>;
			jpgdec_done = <0x102>;
			jpgenc_done = <0x103>;
			venc_mb_done = <0x104>;
			venc_128byte_cnt_done = <0x105>;
			isp_frame_done_a = <0x181>;
			isp_frame_done_b = <0x182>;
			camsv_0_pass1_done = <0x183>;
			camsv_1_pass1_done = <0x184>;
			camsv_2_pass1_done = <0x185>;
			seninf_0_fifo_full = <0x186>;
			seninf_1_fifo_full = <0x187>;
			seninf_2_fifo_full = <0x188>;
			seninf_3_fifo_full = <0x189>;
			seninf_4_fifo_full = <0x18a>;
			seninf_5_fifo_full = <0x18b>;
			seninf_6_fifo_full = <0x18c>;
			seninf_7_fifo_full = <0x18d>;
			apxgpt2_count = <0x10008028>;
			max_prefetch_cnt = <0x04>;
			prefetch_size = <0x118 0x20 0x20 0x20>;
			sram_share_cnt = <0x02>;
			sram_share_engine = <0x0b 0x0c>;
			sram_share_event = <0x1cc 0x1cd>;
			clocks = <0x02 0x0a>;
			clock-names = "GCE";
		};

		cqdma@10212c00 {
			compatible = "mediatek,mt-cqdma-v1";
			reg = <0x10212c00 0x100 0x10212d00 0x100>;
			interrupts = <0x00 0x76 0x08 0x00 0x77 0x08>;
			nr_channel = <0x02>;
		};

		md2md_md2_ccif0@10213000 {
			compatible = "mediatek,md2md_md2_ccif0";
			reg = <0x10213000 0x1000>;
		};

		mipi_tx0@10215000 {
			compatible = "mediatek,mipi_tx0";
			reg = <0x10215000 0x1000>;
		};

		dramc_b_nao@10216000 {
			compatible = "mediatek,dramc_b_nao";
			reg = <0x10216000 0x1000>;
		};

		mipi_rx_ana_csi0@10217000 {
			compatible = "mediatek,mipi_rx_ana_csi0";
			reg = <0x10217000 0x1000>;
		};

		mipi_rx_ana_csi1@10218000 {
			compatible = "mediatek,mipi_rx_ana_csi1";
			reg = <0x10218000 0x1000>;
		};

		ap_cldma@10219000 {
			compatible = "mediatek,ap_cldma";
			reg = <0x10219000 0x1000>;
		};

		md_cldma@1021a000 {
			compatible = "mediatek,md_cldma";
			reg = <0x1021a000 0x1000>;
		};

		mdhw_smi@1021c000 {
			compatible = "mediatek,mdhw_smi";
			reg = <0x1021c000 0x1000>;
		};

		gcpu_rsa@1021d000 {
			compatible = "mediatek,gcpu_rsa";
			reg = <0x1021d000 0x1000>;
		};

		mipi_tx1@1021e000 {
			compatible = "mediatek,mipi_tx1";
			reg = <0x1021e000 0x1000>;
		};

		vad@1021f000 {
			compatible = "mediatek,vad";
			reg = <0x1021f000 0x1000>;
		};

		lastpc@10220000 {
			compatible = "mediatek,mt6797-mcucfg\0mediatek,mt6735-mcucfg";
			reg = <0x10220000 0x1000>;
		};

		lastbus@10220000 {
			compatible = "mediatek,lastbus";
			reg = <0x10220000 0x1000>;
		};

		cpuxgpt@10220000 {
			compatible = "mediatek,mt6797-cpuxgpt";
			reg = <0x10220000 0x1000>;
			interrupts = <0x00 0x40 0x04 0x00 0x41 0x04 0x00 0x42 0x04 0x00 0x43 0x04 0x00 0x44 0x04 0x00 0x45 0x04 0x00 0x46 0x04 0x00 0x47 0x04 0x00 0x142 0x04 0x00 0x143 0x04>;
		};

		mcucfg@10220000 {
			compatible = "mediatek,mcucfg";
			num = <0x02>;
			reg = <0x10220000 0x1000 0x10222000 0x1000>;
		};

		ocp_cfg@10220000 {
			compatible = "mediatek,ocp_cfg";
			reg = <0x10220000 0x4000 0x10005000 0x1000 0x10001000 0x2000 0x10206000 0x1000>;
			interrupts = <0x00 0x149 0x04 0x00 0x14a 0x04 0x00 0x14c 0x04 0x00 0x14d 0x04 0x00 0x14e 0x04 0x00 0x14f 0x04>;
		};

		ptp3_idvfs@10220000 {
			compatible = "mediatek,idvfs";
			reg = <0x11017000 0x1000 0x10005000 0x1000 0x10000000 0x1000 0x10001000 0x2000 0x10206000 0x1000>;
			interrupts = <0x00 0x14b 0x04>;
			clocks = <0x02 0x36>;
			clock-names = "i2c";
		};

		ptpotp@10222000 {
			compatible = "mediatek,ptpotp";
			reg = <0x10222000 0x1000>;
		};

		bpi_bsi_slv0@10228000 {
			compatible = "mediatek,bpi_bsi_slv0";
			reg = <0x10228000 0x1000>;
		};

		bpi_bsi_slv1@10229000 {
			compatible = "mediatek,bpi_bsi_slv1";
			reg = <0x10229000 0x6000>;
		};

		bpi_bsi_slv2@1022f000 {
			compatible = "mediatek,bpi_bsi_slv2";
			reg = <0x1022f000 0x1000>;
		};

		gic@10240000 {
			compatible = "mediatek,gic";
			reg = <0x10240000 0x40000>;
		};

		dbgapb@10300000 {
			compatible = "mediatek,dbgapb";
			reg = <0x10300000 0xd00000>;
			interrupts = <0x00 0x8b 0x08>;
		};

		met_cci400@10390000 {
			compatible = "mediatek,met_cci400";
			reg = <0x10390000 0x10000>;
		};

		cpu_dbgapb {
			compatible = "mediatek,hw_dbg";
			num = <0x0a>;
			reg = <0x10410000 0x1000 0x10510000 0x1000 0x10610000 0x1000 0x10710000 0x1000 0x10810000 0x1000 0x10910000 0x1000 0x10a10000 0x1000 0x10b10000 0x1000 0x10c10000 0x1000 0x10d10000 0x1000>;
		};

		ap_dma@11000000 {
			compatible = "mediatek,ap_dma";
			reg = <0x11000000 0x1000>;
			interrupts = <0x00 0x61 0x08>;
		};

		btif_tx@11000a00 {
			compatible = "mediatek,btif_tx";
			reg = <0x11000a00 0x80>;
			interrupts = <0x00 0x74 0x08>;
		};

		btif_rx@11000a80 {
			compatible = "mediatek,btif_rx";
			reg = <0x11000a80 0x80>;
			interrupts = <0x00 0x75 0x08>;
		};

		adc_hw@11001000 {
			compatible = "mediatek,mt6797-auxadc";
			reg = <0x11001000 0x1000>;
			interrupts = <0x00 0x4a 0x02>;
			clocks = <0x02 0x28>;
			clock-names = "auxadc-main";

			adc_channel@ {
				compatible = "mediatek,adc_channel";
				mediatek,temperature0 = <0x00>;
				mediatek,temperature1 = <0x01>;
				mediatek,adc_fdd_rf_params_dynamic_custom_ch = <0x02>;
				status = "okay";
			};
		};

		apuart0@11002000 {
			cell-index = <0x00>;
			compatible = "mediatek,mt6797-uart";
			reg = <0x11002000 0x1000 0x11000600 0x1000 0x11000680 0x80>;
			interrupts = <0x00 0x5b 0x08 0x00 0x6c 0x08 0x00 0x6d 0x08>;
			clock-frequency = <0x18cba80>;
			clock-div = <0x01>;
			clocks = <0x02 0x16 0x02 0x2e>;
			clock-names = "uart0-main\0uart-apdma";
			pinctrl-names = "uart0_gpio_default\0uart0_rx_set\0uart0_rx_clear\0uart0_tx_set\0uart0_tx_clear";
			pinctrl-0 = <0x3e>;
			pinctrl-1 = <0x3f>;
			pinctrl-2 = <0x40>;
			pinctrl-3 = <0x41>;
			pinctrl-4 = <0x42>;
			status = "okay";
		};

		apuart1@11003000 {
			cell-index = <0x01>;
			compatible = "mediatek,mt6797-uart";
			reg = <0x11003000 0x1000 0x11000700 0x80 0x11000780 0x80>;
			interrupts = <0x00 0x5c 0x08 0x00 0x6e 0x08 0x00 0x6f 0x08>;
			clock-frequency = <0x18cba80>;
			clock-div = <0x01>;
			clocks = <0x02 0x17>;
			clock-names = "uart1-main";
			status = "disabled";
		};

		apuart2@11004000 {
			cell-index = <0x02>;
			compatible = "mediatek,mt6797-uart";
			reg = <0x11004000 0x1000 0x11000800 0x80 0x11000880 0x80>;
			interrupts = <0x00 0x5d 0x08 0x00 0x70 0x08 0x00 0x71 0x08>;
			clock-frequency = <0x18cba80>;
			clock-div = <0x01>;
			clocks = <0x02 0x18>;
			clock-names = "uart2-main";
			status = "disabled";
		};

		apuart3@11005000 {
			cell-index = <0x03>;
			compatible = "mediatek,mt6797-uart";
			reg = <0x11005000 0x1000 0x11000900 0x80 0x11000980 0x80>;
			interrupts = <0x00 0x5e 0x08 0x00 0x72 0x08 0x00 0x73 0x08>;
			clock-frequency = <0x18cba80>;
			clock-div = <0x01>;
			clocks = <0x02 0x19>;
			clock-names = "uart3-main";
			status = "disabled";
		};

		pwm@11006000 {
			compatible = "mediatek,pwm";
			reg = <0x11006000 0x1000>;
			interrupts = <0x00 0x4d 0x08>;
			clocks = <0x02 0x11 0x02 0x12 0x02 0x13 0x02 0x14 0x02 0x10 0x02 0x15>;
			clock-names = "PWM1-main\0PWM2-main\0PWM3-main\0PWM4-main\0PWM-HCLK-main\0PWM-main";
		};

		i2c@11007000 {
			compatible = "mediatek,mt6797-i2c";
			id = <0x00>;
			reg = <0x11007000 0x1000 0x11000100 0x80>;
			interrupts = <0x00 0x54 0x08>;
			clocks = <0x02 0x0c 0x02 0x2e>;
			clock-names = "main\0dma";
			clock-div = <0x0a>;
			#address-cells = <0x01>;
			#size-cells = <0x00>;
			clock-frequency = <0x186a0>;
			mediatek,use-open-drain;

			buck_boost@70 {
				compatible = "mediatek,buck_boost";
				reg = <0x70>;
				status = "okay";
			};

			strobe_main@63 {
				compatible = "mediatek,strobe_main";
				reg = <0x63>;
				status = "okay";
			};

			bq2589x_main@6b {
				compatible = "mediatek,bq2589x_main";
				reg = <0x6b>;
				status = "okay";
				pinctrl-names = "chg0_dis_low_cfg\0chg0_dis_high_cfg\0chg1_dis_low_cfg\0chg1_dis_high_cfg";
				pinctrl-0 = <0x43>;
				pinctrl-1 = <0x44>;
				pinctrl-2 = <0x45>;
				pinctrl-3 = <0x46>;
			};

			bq27532@55 {
				compatible = "mediatek,bq27532";
				reg = <0x55>;
				status = "okay";
			};

			tsu6721@25 {
				compatible = "mediatek,tsu6721";
				reg = <0x25>;
				status = "okay";
			};

			lcd_bl_bias@11 {
				compatible = "mediatek,lcd_bl_bias";
				reg = <0x11>;
				status = "okay";
			};

			fusb301a_type_c@21 {
				compatible = "mediatek,fusb301a_type_c";
				reg = <0x21>;
				status = "okay";
			};

			tusb320_type_c@60 {
				compatible = "mediatek,tusb320_type_c";
				reg = <0x47>;
				status = "okay";
			};
		};

		i2c@11008000 {
			compatible = "mediatek,mt6797-i2c";
			id = <0x01>;
			reg = <0x11008000 0x1000 0x11000180 0x80>;
			interrupts = <0x00 0x55 0x08>;
			clocks = <0x02 0x0d 0x02 0x2e>;
			clock-names = "main\0dma";
			clock-div = <0x0a>;
			#address-cells = <0x01>;
			#size-cells = <0x00>;
			clock-frequency = <0x61a80>;
			mediatek,use-open-drain;

			apds9922@53 {
				compatible = "mediatek,apds9922";
				tpvddi-supply = <0x47>;
				interrupt-parent = <0x33>;
				interrupts = <0x55 0x02>;
				debounce = <0x55 0x00>;
				gpio = <0x55>;
				reg = <0x53>;
				status = "okay";
			};

			lsm6ds3@6a {
				compatible = "mediatek,lsm6ds3";
				interrupt-parent = <0x33>;
				interrupts = <0x3f 0x01>;
				debounce = <0x3f 0x00>;
				reg = <0x6a>;
				status = "okay";
			};
		};

		i2c@11009000 {
			compatible = "mediatek,mt6797-i2c";
			id = <0x08>;
			reg = <0x11009000 0x1000 0x11000200 0x80>;
			interrupts = <0x00 0x56 0x08>;
			clocks = <0x02 0x0e 0x02 0x2e 0x02 0x39>;
			clock-names = "main\0dma\0arb";
			clock-div = <0x0a>;
			#address-cells = <0x01>;
			#size-cells = <0x00>;
			clock-frequency = <0x61a80>;
			mediatek,use-open-drain;
		};

		spi@1100a000 {
			compatible = "mediatek,mt6797-spi";
			cell-index = <0x00>;
			spi-padmacro = <0x00>;
			reg = <0x1100a000 0x1000>;
			interrupts = <0x00 0x7a 0x08>;
			clocks = <0x02 0x20>;
			clock-names = "spi-main";
			clock-frequency = <0x67f3540>;
			clock-div = <0x01>;
		};

		therm_ctrl@1100b000 {
			compatible = "mediatek,mt6797-therm_ctrl";
			reg = <0x1100b000 0x1000>;
			interrupts = <0x00 0x4e 0x08>;
			clocks = <0x02 0x0b>;
			clock-names = "therm-main";
		};

		eem_fsm@1100b000 {
			compatible = "mediatek,mt6797-eem_fsm";
			reg = <0x1100b000 0x1000>;
			interrupts = <0x00 0x81 0x08>;
			clocks = <0x48 0x01 0x34 0x07 0x02 0x0b>;
			clock-names = "mfg-main\0mtcmos-mfg\0therm-eem";
		};

		btif@1100c000 {
			compatible = "mediatek,btif";
			reg = <0x1100c000 0x1000>;
			interrupts = <0x00 0x82 0x08>;
			clocks = <0x02 0x1e 0x02 0x2e>;
			clock-names = "btifc\0apdmac";
		};

		i2c@1100d000 {
			compatible = "mediatek,mt6797-i2c";
			id = <0x09>;
			reg = <0x1100d000 0x1000 0x11000280 0x80>;
			interrupts = <0x00 0x57 0x08>;
			clocks = <0x02 0x0f 0x02 0x2e 0x02 0x3b>;
			clock-names = "main\0dma\0arb";
			clock-div = <0x0a>;
			#address-cells = <0x01>;
			#size-cells = <0x00>;
			clock-frequency = <0x61a80>;
			mediatek,use-open-drain;
		};

		i2c@1100e000 {
			compatible = "mediatek,mt6797-i2c";
			id = <0x06>;
			reg = <0x1100e000 0x1000 0x11000500 0x80>;
			interrupts = <0x00 0x58 0x08>;
			clocks = <0x02 0x36 0x02 0x2e>;
			clock-names = "main\0dma";
			clock-div = <0x0a>;
			#address-cells = <0x01>;
			#size-cells = <0x00>;
			clock-frequency = <0x33e140>;
			mediatek,use-push-pull;

			vproc_buck@68 {
				compatible = "mediatek,vproc_buck";
				reg = <0x68>;
				status = "okay";
			};
		};

		pwm_disp@1100f000 {
			compatible = "mediatek,pwm_disp";
			reg = <0x1100f000 0x1000>;
		};

		i2c@11010000 {
			compatible = "mediatek,mt6797-i2c";
			id = <0x07>;
			reg = <0x11010000 0x1000 0x11000580 0x80>;
			interrupts = <0x00 0x59 0x08>;
			clocks = <0x02 0x37 0x02 0x2e>;
			clock-names = "main\0dma";
			clock-div = <0x0a>;
			#address-cells = <0x01>;
			#size-cells = <0x00>;
			clock-frequency = <0x33e140>;
			mediatek,use-push-pull;

			rt5735_buck@1c {
				compatible = "mediatek,rt5735";
				reg = <0x1c>;
				regulator-name = "vgpu_buck_rt5735";
				regulator-min-microvolt = <0x927c0>;
				regulator-max-microvolt = <0x154456>;
				regulator-ramp-delay = <0x7d00>;
				regulator-enable-ramp-delay = <0x320>;
				status = "okay";
			};

			fan53200_buck@60 {
				compatible = "mediatek,fan53200";
				reg = <0x60>;
				regulator-name = "vgpu_buck_fan53200";
				regulator-min-microvolt = <0x927c0>;
				regulator-max-microvolt = <0x152bec>;
				regulator-ramp-delay = <0x7d00>;
				regulator-enable-ramp-delay = <0x320>;
				status = "okay";
			};
		};

		i2c@11011000 {
			compatible = "mediatek,mt6797-i2c";
			id = <0x04>;
			reg = <0x11011000 0x1000 0x11000300 0x80>;
			interrupts = <0x00 0x5a 0x08>;
			clocks = <0x02 0x35 0x02 0x2e>;
			clock-names = "main\0dma";
			clock-div = <0x0a>;
			#address-cells = <0x01>;
			#size-cells = <0x00>;
			clock-frequency = <0x61a80>;
			mediatek,use-open-drain;

			cap_touch@20 {
				compatible = "mediatek,cap_touch";
				reg = <0x20>;
				status = "okay";
			};
		};

		spi@11012000 {
			compatible = "mediatek,mt6797-spi";
			cell-index = <0x01>;
			spi-padmacro = <0x01>;
			reg = <0x11012000 0x1000>;
			interrupts = <0x00 0x83 0x08>;
			clocks = <0x02 0x3e>;
			clock-names = "spi-main";
			clock-frequency = <0x67f3540>;
			clock-div = <0x01>;
			#address-cells = <0x01>;
			#size-cells = <0x00>;
			pinctrl-names = "spi1_gpio_def\0spi1_cs_set\0spi1_cs_clr\0spi1_clk_set\0spi1_clk_clr\0spi1_miso_set\0spi1_miso_clr\0spi1_mosi_set\0spi1_mosi_clr";
			pinctrl-0 = <0x49>;
			pinctrl-1 = <0x4a>;
			pinctrl-2 = <0x4b>;
			pinctrl-3 = <0x4c>;
			pinctrl-4 = <0x4d>;
			pinctrl-5 = <0x4e>;
			pinctrl-6 = <0x4f>;
			pinctrl-7 = <0x50>;
			pinctrl-8 = <0x51>;
			status = "okay";

			fingerprint_gf@0 {
				compatible = "goodix,goodix-fp";
				reg = <0x00>;
				spi-max-frequency = <0x7a1200>;
				netlink-event = <0x1a>;
				status = "okay";
			};
		};

		i2c@11013000 {
			compatible = "mediatek,mt6797-i2c";
			id = <0x02>;
			reg = <0x11013000 0x1000 0x11000400 0x80>;
			interrupts = <0x00 0x5f 0x08>;
			clocks = <0x02 0x38 0x02 0x2e 0x02 0x39>;
			clock-names = "main\0dma\0arb";
			clock-div = <0x0a>;
			#address-cells = <0x01>;
			#size-cells = <0x00>;
			clock-frequency = <0x493e0>;
			mediatek,use-open-drain;

			tfa98xx@34 {
				compatible = "nxp,tfa98xx";
				reg = <0x34>;
				nxp,tfa_max-vol-steps = <0x01>;
				reset-gpio = <0x0a 0xff 0x00>;
				irq-gpio = <0x0a 0x47 0x00>;
				pinctrl-names = "tfa_rst0\0tfa_rst1\0tfa_eint";
				pinctrl-0 = <0x52>;
				pinctrl-1 = <0x53>;
				pinctrl-2 = <0x54>;
				status = "okay";
			};
		};

		i2c@11014000 {
			compatible = "mediatek,mt6797-i2c";
			id = <0x03>;
			reg = <0x11014000 0x1000 0x11000480 0x80>;
			interrupts = <0x00 0x60 0x08>;
			clocks = <0x02 0x3a 0x02 0x2e 0x02 0x3b>;
			clock-names = "main\0dma\0arb";
			clock-div = <0x0a>;
			#address-cells = <0x01>;
			#size-cells = <0x00>;
			clock-frequency = <0x61a80>;
			mediatek,use-open-drain;

			camera_main@1a {
				compatible = "mediatek,camera_main";
				reg = <0x1a>;
				status = "okay";
			};

			camera_main_af@0c {
				compatible = "mediatek,camera_main_af";
				reg = <0x0c>;
				status = "okay";
			};

			camera_sub@36 {
				compatible = "mediatek,camera_sub";
				reg = <0x36>;
				status = "okay";
			};
		};

		dvfsp@11015000 {
			compatible = "mediatek,mt6797-dvfsp";
			reg = <0x11015000 0x1000 0x12a000 0x3000>;
			interrupts = <0x00 0xa1 0x08>;
			clocks = <0x02 0x36>;
			clock-names = "i2c";
		};

		dvfs_proc2@11016000 {
			compatible = "mediatek,dvfs_proc2";
			reg = <0x11016000 0x1000>;
			interrupts = <0x00 0xa5 0x00>;
		};

		spi@11018000 {
			compatible = "mediatek,mt6797-spi";
			cell-index = <0x02>;
			spi-padmacro = <0x01>;
			reg = <0x11018000 0x1000>;
			interrupts = <0x00 0x84 0x08>;
			clocks = <0x02 0x46>;
			clock-names = "spi-main";
			clock-frequency = <0x67f3540>;
			clock-div = <0x01>;
			status = "disabled";
		};

		spi@11019000 {
			compatible = "mediatek,mt6797-spi";
			cell-index = <0x03>;
			spi-padmacro = <0x00>;
			reg = <0x11019000 0x1000>;
			interrupts = <0x00 0x85 0x08>;
			clocks = <0x02 0x47>;
			clock-names = "spi-main";
			clock-frequency = <0x67f3540>;
			clock-div = <0x01>;
			status = "disabled";
		};

		spi@1101a000 {
			compatible = "mediatek,mt6797-spi";
			cell-index = <0x04>;
			spi-padmacro = <0x00>;
			reg = <0x1101a000 0x1000>;
			interrupts = <0x00 0x86 0x08>;
			clocks = <0x02 0x48>;
			clock-names = "spi-main";
			clock-frequency = <0x67f3540>;
			clock-div = <0x01>;
			status = "disabled";
		};

		spi@1101b000 {
			compatible = "mediatek,mt6797-spi";
			cell-index = <0x05>;
			spi-padmacro = <0x00>;
			reg = <0x1101b000 0x1000>;
			interrupts = <0x00 0x87 0x08>;
			clocks = <0x02 0x49>;
			clock-names = "spi-main";
			clock-frequency = <0x67f3540>;
			clock-div = <0x01>;
			status = "disabled";
		};

		i2c@1101c000 {
			compatible = "mediatek,mt6797-i2c";
			id = <0x05>;
			reg = <0x1101c000 0x1000 0x11000380 0x80>;
			interrupts = <0x00 0x53 0x08>;
			clocks = <0x02 0x3c 0x02 0x2e>;
			clock-names = "main\0dma";
			clock-div = <0x0a>;
			#address-cells = <0x01>;
			#size-cells = <0x00>;
			clock-frequency = <0x61a80>;
			mediatek,use-open-drain;

			bq2589x_sub@6b {
				compatible = "mediatek,bq2589x_sed";
				reg = <0x6b>;
				status = "okay";
			};

			motor@5a {
				compatible = "mediatek,motor";
				reg = <0x5a>;
				status = "okay";
				pinctrl-names = "default\0low_cfg\0high_cfg";
				pinctrl-0 = <0x55>;
				pinctrl-1 = <0x56>;
				pinctrl-2 = <0x57>;
			};
		};

		irtx@1101d000 {
			compatible = "mediatek,irtx";
			reg = <0x1101d000 0x1000>;
			interrupts = <0x00 0xa8 0x04>;
			pwm_ch = <0x03>;
			clock-frequency = <0x18cba80>;
			clock-div = <0x01>;
			clocks = <0x02 0x4a>;
			clock-names = "clk-irtx-main";
			pinctrl-names = "irtx_gpio_default", "irtx_gpio_led_set";
			pinctrl-0 = <0xb3>;
			pinctrl-1 = <0xb4>;
			status = "okay";
		};

		anc_md32@11020000 {
			compatible = "mediatek,anc_md32";
			reg = <0x11020000 0x6000>;
		};

		audio@11220000 {
			compatible = "mediatek,audio";
			reg = <0x11220000 0x10000>;
			interrupts = <0x00 0x97 0x08>;
			#clock-cells = <0x01>;
			linux,phandle = <0x58>;
			phandle = <0x58>;
		};

		mt_soc_dl1_pcm@11220000 {
			compatible = "mediatek,mt-soc-dl1-pcm";
			reg = <0x11220000 0x1000>;
			interrupts = <0x00 0x97 0x08>;
			clocks = <0x58 0x09 0x58 0x03 0x58 0x02 0x58 0x04 0x58 0x08 0x58 0x07 0x58 0x05 0x58 0x06 0x58 0x01 0x58 0x0b 0x58 0x0a 0x34 0x0e 0x02 0x32 0x02 0x4d 0x02 0x4e 0x02 0x40 0x02 0x41 0x59 0x1b 0x59 0x1c 0x59 0x4c 0x59 0x4d 0x59 0x14 0x59 0x30 0x59 0x15 0x59 0x26 0x59 0x21 0x59 0x25 0x5a 0x0a 0x5a 0x0b 0x5b>;
			clock-names = "aud_afe_clk\0aud_dac_clk\0aud_dac_predis_clk\0aud_adc_clk\0aud_apll22m_clk\0aud_apll24m_clk\0aud_apll1_tuner_clk\0aud_apll2_tuner_clk\0aud_tml_clk\0aud_adc_hires_clk\0aud_adc_hires_tml_clk\0scp_sys_audio\0aud_infra_clk\0aud_infra_26m\0aud_infra_26m_pad_top\0aud_infra_anc_md32\0aud_infra_anc_md32_32k\0aud_mux1_clk\0aud_mux2_clk\0top_ad_apll1_clk\0top_ad_apll2_clk\0top_mux_audio\0top_sys_pll3_d4\0top_mux_audio_int\0top_sys_pll1_d4\0top_mux_anc_md32\0top_sys_pll1_d2\0apmixed_apll1_clk\0apmixed_apll2_clk\0top_clk26m_clk";
			pinctrl-names = "aud_clk_mosi_off\0aud_clk_mosi_on\0aud_smartpa_mode0\0aud_smartpa_mode1\0aud_smartpa_mode3\0aud_tdm_mode0\0aud_tdm_mode1\0hpdepop-pullhigh\0hpdepop-pulllow\0aud_dat_miso_off\0aud_dat_miso_on\0aud_dat_mosi_off\0aud_dat_mosi_on\0vow_dat_miso_off\0vow_dat_miso_on\0vow_clk_miso_off\0vow_clk_miso_on\0anc_dat_mosi_off\0anc_dat_mosi_on\0aud_smartpa_mode2";
			pinctrl-0 = <0x5c>;
			pinctrl-1 = <0x5d>;
			pinctrl-2 = <0x5e>;
			pinctrl-3 = <0x5f>;
			pinctrl-4 = <0x60>;
			pinctrl-5 = <0x61>;
			pinctrl-6 = <0x62>;
			pinctrl-7 = <0x63>;
			pinctrl-8 = <0x64>;
			pinctrl-9 = <0x65>;
			pinctrl-10 = <0x66>;
			pinctrl-11 = <0x67>;
			pinctrl-12 = <0x68>;
			pinctrl-13 = <0x69>;
			pinctrl-14 = <0x6a>;
			pinctrl-15 = <0x6b>;
			pinctrl-16 = <0x6c>;
			pinctrl-17 = <0x6d>;
			pinctrl-18 = <0x6e>;
			pinctrl-19 = <0x6f>;
			status = "okay";
		};

		mt_soc_ul1_pcm@11220000 {
			compatible = "mediatek,mt_soc_pcm_capture";
		};

		mt_soc_voice_md1@11220000 {
			compatible = "mediatek,mt_soc_pcm_voice_md1";
		};

		mt_soc_hdmi_pcm@11220000 {
			compatible = "mediatek,mt_soc_pcm_hdmi";
		};

		mt_soc_uldlloopback_pcm@11220000 {
			compatible = "mediatek,mt_soc_pcm_uldlloopback";
		};

		mt_soc_i2s0_pcm@11220000 {
			compatible = "mediatek,mt_soc_pcm_dl1_i2s0";
		};

		mt_soc_mrgrx_pcm@11220000 {
			compatible = "mediatek,mt_soc_pcm_mrgrx";
		};

		mt_soc_mrgrx_awb_pcm@11220000 {
			compatible = "mediatek,mt_soc_pcm_mrgrx_awb";
		};

		mt_soc_fm_i2s_pcm@11220000 {
			compatible = "mediatek,mt_soc_pcm_fm_i2s";
		};

		mt_soc_fm_i2s_awb_pcm@11220000 {
			compatible = "mediatek,mt_soc_pcm_fm_i2s_awb";
		};

		mt_soc_i2s0dl1_pcm@11220000 {
			compatible = "mediatek,mt_soc_pcm_dl1_i2s0dl1";
		};

		mt_soc_dl1_awb_pcm@11220000 {
			compatible = "mediatek,mt_soc_pcm_dl1_awb";
		};

		mt_soc_voice_md1_bt@11220000 {
			compatible = "mediatek,mt_soc_pcm_voice_md1_bt";
		};

		mt_soc_voip_bt_out@11220000 {
			compatible = "mediatek,mt_soc_pcm_dl1_bt";
		};

		mt_soc_voip_bt_in@11220000 {
			compatible = "mediatek,mt_soc_pcm_bt_dai";
		};

		mt_soc_tdmrx_pcm@11220000 {
			compatible = "mediatek,mt_soc_tdm_capture";
		};

		mt_soc_fm_mrgtx_pcm@11220000 {
			compatible = "mediatek,mt_soc_pcm_fmtx";
		};

		mt_soc_ul2_pcm@11220000 {
			compatible = "mediatek,mt_soc_pcm_capture2";
		};

		mt_soc_i2s0_awb_pcm@11220000 {
			compatible = "mediatek,mt_soc_pcm_i2s0_awb";
		};

		mt_soc_voice_md2@11220000 {
			compatible = "mediatek,mt_soc_pcm_voice_md2";
		};

		mt_soc_routing_pcm@11220000 {
			compatible = "mediatek,mt_soc_pcm_routing";
		};

		mt_soc_voice_md2_bt@11220000 {
			compatible = "mediatek,mt_soc_pcm_voice_md2_bt";
		};

		mt_soc_hp_impedance_pcm@11220000 {
			compatible = "mediatek,mt_soc_pcm_hp_impedance";
		};

		mt_soc_codec_name@11220000 {
			compatible = "mediatek,mt_soc_codec_63xx";
			use_hp_depop_flow = <0x00>;
		};

		mt_soc_dummy_pcm@11220000 {
			compatible = "mediatek,mt_soc_pcm_dummy";
		};

		mt_soc_codec_dummy_name@11220000 {
			compatible = "mediatek,mt_soc_codec_dummy";
		};

		mt_soc_routing_dai_name@11220000 {
			compatible = "mediatek,mt_soc_dai_routing";
		};

		mt_soc_dai_name@11220000 {
			compatible = "mediatek,mt_soc_dai_stub";
		};

		mt_soc_dl2_pcm@11220000 {
			compatible = "mediatek,mt_soc_pcm_dl2";
		};

		mt_soc_anc_pcm@11220000 {
			compatible = "mediatek,mt_soc_pcm_anc";
		};

		icusb@11200000 {
			compatible = "mediatek,icusb";
			reg = <0x11200000 0x10000 0x11210000 0x10000>;
			reg-names = "musbfsh_base\0musbfsh_sif";
			interrupts = <0x00 0x49 0x08>;
			clocks = <0x02 0x09 0x02 0x4c>;
			clock-names = "infra_icusb\0sssub_ref_clk";
		};

		usb1p_sif@11210000 {
			compatible = "mediatek,usb1p_sif";
			reg = <0x11210000 0x10000>;
		};

		usb3@11270000 {
			compatible = "mediatek,usb3";
			reg = <0x11270000 0x10000 0x11280000 0x10000 0x11290000 0x10000>;
			reg-names = "ssusb_base\0ssusb_sif\0ssusb_sif2";
			interrupts = <0x00 0x7f 0x08 0x00 0x7e 0x08>;
			interrupt-names = "musb-hdrc\0xhci";
			pinctrl-names = "iddig_default\0iddig_init";
			pinctrl-0 = <0x70>;
			pinctrl-1 = <0x71>;
			status = "okay";
		};

		usb3_xhci@11270000 {
			compatible = "mediatek,usb3_xhci";
			reg = <0x11270000 0x10000 0x11280000 0x10000 0x11290000 0x10000>;
			reg-names = "ssusb_base\0ssusb_sif\0ssusb_sif2";
			interrupts = <0x00 0x7e 0x08>;
			interrupt-names = "xhci";
			pinctrl-names = "drvvbus_default\0drvvbus_low\0drvvbus_high";
			pinctrl-0 = <0x72>;
			pinctrl-1 = <0x73>;
			pinctrl-2 = <0x74>;
			status = "okay";
		};

		usb_c_pinctrl@0 {
			compatible = "mediatek,usb_c_pinctrl";
			pinctrl-names = "default\0eint_init\0gpio_en_low\0gpio_en_high";
			pinctrl-0 = <0x75>;
			pinctrl-1 = <0x76>;
			pinctrl-2 = <0x77>;
			pinctrl-3 = <0x78>;
			status = "okay";
		};

		usb3_phy {
			compatible = "mediatek,usb3_phy";
			clocks = <0x02 0x45 0x02 0x4b 0x02 0x4c 0x59 0x1d 0x59 0x42>;
			clock-names = "ssusb_bus_clk\0ssusb_sys_clk\0ssusb_ref_clk\0ssusb_top_sys_sel_clk\0ssusb_univpll3_d2_clk";
		};

		usb3_sif@11280000 {
			compatible = "mediatek,usb3_sif";
			reg = <0x11280000 0x10000>;
		};

		usb3_sif2@11290000 {
			compatible = "mediatek,usb3_sif2";
			reg = <0x11290000 0x10000>;
		};

		mjc_config@12000000 {
			compatible = "mediatek,mjc_config-v1";
			reg = <0x12000000 0x1000>;
			interrupts = <0x00 0xf4 0x08>;
			#clock-cells = <0x01>;
			linux,phandle = <0x3c>;
			phandle = <0x3c>;
		};

		mjc_top@12001000 {
			compatible = "mediatek,mjc_top-v1";
			reg = <0x12001000 0x1000>;
			interrupts = <0x00 0xf3 0x08>;
			clocks = <0x38 0x01 0x38 0x25 0x38 0x26 0x3c 0x01 0x3c 0x02 0x3c 0x03 0x3c 0x04 0x3c 0x06 0x34 0x03 0x34 0x0c 0x59 0x19 0x59 0x50 0x59 0x41>;
			clock-names = "smi-common\0larb4-axi-asif-mm\0larb4-axi-asif-mjc\0mjc-smi-larb\0top-clk-0\0top-clk-1\0top-clk-2\0larb4-asif\0mtcmos-dis\0mtcmos-mjc\0mux_mjc\0imgpll_ck\0univpll_d5";
		};

		smi_larb4@12002000 {
			compatible = "mediatek,smi_larb4";
			reg = <0x12002000 0x1000>;
			interrupts = <0x00 0xf2 0x08>;
		};

		g3d_config@13000000 {
			compatible = "mediatek,g3d_config";
			reg = <0x13000000 0x1000>;
			#clock-cells = <0x01>;
			linux,phandle = <0x48>;
			phandle = <0x48>;
		};

		g3d_vad_config@13001000 {
			compatible = "mediatek,g3d_vad_config";
			reg = <0x13001000 0x1000>;
		};

		g3d_dfp_config@13020000 {
			compatible = "mediatek,g3d_dfp_config";
			reg = <0x13020000 0x1000>;
		};

		mali@13040000 {
			compatible = "arm,malit860\0arm,mali-t86x\0arm,malit8xx\0arm,mali-midgard";
			reg = <0x13040000 0x4000>;
			interrupts = <0x00 0x108 0x08 0x00 0x107 0x08 0x00 0x106 0x08>;
			interrupt-names = "JOB\0MMU\0GPU";
			clock-frequency = <0x29b92700>;
			clocks = <0x48 0x01 0x02 0x53 0x34 0x06 0x34 0x07 0x34 0x0b 0x34 0x0a 0x34 0x09 0x34 0x08 0x59 0x22 0x59 0x40 0x02 0x42 0x02 0x37 0x02 0x2e>;
			clock-names = "mfg-main\0mfg52m-vcg\0mtcmos-mfg-async\0mtcmos-mfg\0mtcmos-mfg-core0\0mtcmos-mfg-core1\0mtcmos-mfg-core2\0mtcmos-mfg-core3\0mux-mfg52m\0mux-univpll2-d8\0infra-dvfs-gpu\0infra-gpupm\0infra-ap-dma";
		};

		mmsys_config@14000000 {
			compatible = "mediatek,mmsys_config";
			reg = <0x14000000 0x1000>;
			interrupts = <0x00 0xe8 0x08>;
			#clock-cells = <0x01>;
			clocks = <0x38 0x04>;
			clock-names = "CAM_MDP";
			linux,phandle = <0x38>;
			phandle = <0x38>;
		};

		lcm_mode {
			compatible = "mediatek,lcm_mode";
		};

		dispsys@14000000 {
			compatible = "mediatek,mt6797-dispsys";
			reg = <0x14000000 0x1000 0x1400b000 0x1000 0x1400c000 0x1000 0x1400f000 0x1000 0x14010000 0x1000 0x14011000 0x1000 0x14013000 0x1000 0x14014000 0x1000 0x14015000 0x1000 0x14016000 0x1000 0x14017000 0x1000 0x14018000 0x1000 0x14019000 0x1000 0x1401a000 0x1000 0x1401b000 0x1000 0x1401c000 0x1000 0x1401d000 0x1000 0x1401e000 0x1000 0x1100f000 0x1000 0x1401f000 0x1000 0x14020000 0x1000 0x14021000 0x1000 0x14022000 0x1000 0x14012000 0x1000 0x1400d000 0x1000 0x1400e000 0x1000 0x10215000 0x1000 0x1021e000 0x1000>;
			interrupts = <0x00 0x00 0x08 0x00 0xd5 0x08 0x00 0xd6 0x08 0x00 0xd9 0x08 0x00 0xda 0x08 0x00 0xdb 0x08 0x00 0xdd 0x08 0x00 0xde 0x08 0x00 0xdf 0x08 0x00 0xe0 0x08 0x00 0xe1 0x08 0x00 0xe2 0x08 0x00 0xe3 0x08 0x00 0xe4 0x08 0x00 0x00 0x08 0x00 0xe5 0x08 0x00 0xe6 0x08 0x00 0xe7 0x08 0x00 0x00 0x08 0x00 0xca 0x08 0x00 0xe9 0x08 0x00 0xea 0x08 0x00 0x00 0x08 0x00 0xdc 0x08 0x00 0xd7 0x08 0x00 0xd8 0x08 0x00 0x00 0x08 0x00 0x00 0x08>;
			clocks = <0x38 0x01 0x38 0x02 0x38 0x03 0x38 0x10 0x38 0x11 0x38 0x12 0x38 0x13 0x38 0x14 0x38 0x15 0x38 0x16 0x38 0x17 0x38 0x18 0x38 0x19 0x38 0x1a 0x38 0x1b 0x38 0x1c 0x38 0x1d 0x38 0x1e 0x38 0x1f 0x38 0x20 0x38 0x21 0x38 0x29 0x38 0x22 0x38 0x2a 0x38 0x23 0x38 0x24 0x38 0x27 0x02 0x2d 0x34 0x03 0x59 0x1a 0x59 0x57 0x59 0x58 0x59 0x59 0x59 0x5a 0x59 0x56 0x59 0x07 0x59 0x3f 0x59 0x47 0x59 0x48 0x59 0x4a 0x59 0x4b 0x59 0x49>;
			clock-names = "DISP0_SMI_COMMON\0DISP0_SMI_LARB0\0DISP0_SMI_LARB5\0DISP0_DISP_OVL0\0DISP0_DISP_OVL1\0DISP0_DISP_OVL0_2L\0DISP0_DISP_OVL1_2L\0DISP0_DISP_RDMA0\0DISP0_DISP_RDMA1\0DISP0_DISP_WDMA0\0DISP0_DISP_WDMA1\0DISP0_DISP_COLOR\0DISP0_DISP_CCORR\0DISP0_DISP_AAL\0DISP0_DISP_GAMMA\0DISP0_DISP_OD\0DISP0_DISP_DITHER\0DISP0_DISP_UFOE\0DISP0_DISP_DSC\0DISP0_DISP_SPLIT\0DISP1_DSI0_MM_CLOCK\0DISP1_DSI0_INTERFACE_CLOCK\0DISP1_DSI1_MM_CLOCK\0DISP1_DSI1_INTERFACE_CLOCK\0DISP1_DPI_MM_CLOCK\0DISP1_DPI_INTERFACE_CLOCK\0DISP1_DISP_OVL0_MOUT\0DISP_PWM\0DISP_MTCMOS_CLK\0MUX_DPI0\0TVDPLL_D2\0TVDPLL_D4\0TVDPLL_D8\0TVDPLL_D16\0DPI_CK\0MUX_PWM\0UNIVPLL2_D4\0ULPOSC_D2\0ULPOSC_D3\0ULPOSC_D8\0ULPOSC_D10\0ULPOSC_D4";
		};

		mdp_rdma0@14001000 {
			compatible = "mediatek,mdp_rdma0";
			reg = <0x14001000 0x1000>;
			interrupts = <0x00 0xcb 0x08>;
			clocks = <0x38 0x05>;
			clock-names = "MDP_RDMA0";
		};

		mdp_rdma1@14002000 {
			compatible = "mediatek,mdp_rdma1";
			reg = <0x14002000 0x1000>;
			interrupts = <0x00 0xcc 0x08>;
			clocks = <0x38 0x06>;
			clock-names = "MDP_RDMA1";
		};

		mdp_rsz0@14003000 {
			compatible = "mediatek,mdp_rsz0";
			reg = <0x14003000 0x1000>;
			interrupts = <0x00 0xcd 0x08>;
			clocks = <0x38 0x07>;
			clock-names = "MDP_RSZ0";
		};

		mdp_rsz1@14004000 {
			compatible = "mediatek,mdp_rsz1";
			reg = <0x14004000 0x1000>;
			interrupts = <0x00 0xce 0x08>;
			clocks = <0x38 0x08>;
			clock-names = "MDP_RSZ1";
		};

		mdp_rsz2@14005000 {
			compatible = "mediatek,mdp_rsz2";
			reg = <0x14005000 0x1000>;
			interrupts = <0x00 0xcf 0x08>;
			clocks = <0x38 0x09>;
			clock-names = "MDP_RSZ2";
		};

		mdp_wdma@14006000 {
			compatible = "mediatek,mdp_wdma";
			reg = <0x14006000 0x1000>;
			interrupts = <0x00 0xd2 0x08>;
			clocks = <0x38 0x0c>;
			clock-names = "MDP_WDMA";
		};

		mdp_wrot0@14007000 {
			compatible = "mediatek,mdp_wrot0";
			reg = <0x14007000 0x1000>;
			interrupts = <0x00 0xd3 0x08>;
			clocks = <0x38 0x0d>;
			clock-names = "MDP_WROT0";
		};

		mdp_wrot1@14008000 {
			compatible = "mediatek,mdp_wrot1";
			reg = <0x14008000 0x1000>;
			interrupts = <0x00 0xd4 0x08>;
			clocks = <0x38 0x0e>;
			clock-names = "MDP_WROT1";
		};

		mdp_tdshp@14009000 {
			compatible = "mediatek,mdp_tdshp";
			reg = <0x14009000 0x1000>;
			interrupts = <0x00 0xd0 0x08>;
			clocks = <0x38 0x0a>;
			clock-names = "MDP_TDSHP";
		};

		mdp_color@1400a000 {
			compatible = "mediatek,mdp_color";
			reg = <0x1400a000 0x1000>;
			interrupts = <0x00 0xd1 0x08>;
			clocks = <0x38 0x0b>;
			clock-names = "MDP_COLOR";
		};

		disp_ovl0@1400b000 {
			compatible = "mediatek,disp_ovl0";
			reg = <0x1400b000 0x1000>;
			interrupts = <0x00 0xd5 0x08>;
		};

		disp_ovl1@1400c000 {
			compatible = "mediatek,disp_ovl1";
			reg = <0x1400c000 0x1000>;
			interrupts = <0x00 0xd6 0x08>;
		};

		disp_ovl0_2l@1400d000 {
			compatible = "mediatek,disp_ovl0_2l";
			reg = <0x1400d000 0x1000>;
			interrupts = <0x00 0xd7 0x08>;
		};

		disp_ovl1_2l@1400e000 {
			compatible = "mediatek,disp_ovl1_2l";
			reg = <0x1400e000 0x1000>;
			interrupts = <0x00 0xd8 0x08>;
		};

		disp_rdma0@1400f000 {
			compatible = "mediatek,disp_rdma0";
			reg = <0x1400f000 0x1000>;
			interrupts = <0x00 0xd9 0x08>;
		};

		disp_rdma1@14010000 {
			compatible = "mediatek,disp_rdma1";
			reg = <0x14010000 0x1000>;
			interrupts = <0x00 0xda 0x08>;
		};

		disp_wdma0@14011000 {
			compatible = "mediatek,disp_wdma0";
			reg = <0x14011000 0x1000>;
			interrupts = <0x00 0xdb 0x08>;
		};

		disp_wdma1@14012000 {
			compatible = "mediatek,disp_wdma1";
			reg = <0x14012000 0x1000>;
			interrupts = <0x00 0xdc 0x08>;
		};

		disp_color@14013000 {
			compatible = "mediatek,disp_color";
			reg = <0x14013000 0x1000>;
			interrupts = <0x00 0xdd 0x08>;
		};

		disp_ccorr@14014000 {
			compatible = "mediatek,disp_ccorr";
			reg = <0x14014000 0x1000>;
			interrupts = <0x00 0xde 0x08>;
		};

		disp_aal@14015000 {
			compatible = "mediatek,disp_aal";
			reg = <0x14015000 0x1000>;
			interrupts = <0x00 0xdf 0x08>;
		};

		disp_gamma@14016000 {
			compatible = "mediatek,disp_gamma";
			reg = <0x14016000 0x1000>;
			interrupts = <0x00 0xe0 0x08>;
		};

		disp_od@14017000 {
			compatible = "mediatek,disp_od";
			reg = <0x14017000 0x1000>;
			interrupts = <0x00 0xe1 0x08>;
		};

		disp_dither@14018000 {
			compatible = "mediatek,disp_dither";
			reg = <0x14018000 0x1000>;
			interrupts = <0x00 0xe2 0x08>;
		};

		dsi_ufoe@14019000 {
			compatible = "mediatek,dsi_ufoe";
			reg = <0x14019000 0x1000>;
			interrupts = <0x00 0xe3 0x08>;
		};

		dsi_dsc@1401a000 {
			compatible = "mediatek,dsi_dsc";
			reg = <0x1401a000 0x1000>;
			interrupts = <0x00 0xe4 0x08>;
		};

		dsi_split@1401b000 {
			compatible = "mediatek,dsi_split";
			reg = <0x1401b000 0x1000>;
		};

		dsi0@1401c000 {
			compatible = "mediatek,dsi0";
			reg = <0x1401c000 0x1000>;
			interrupts = <0x00 0xe5 0x08>;
		};

		dsi1@1401d000 {
			compatible = "mediatek,dsi1";
			reg = <0x1401d000 0x1000>;
			interrupts = <0x00 0xe6 0x08>;
		};

		dpi0@1401e000 {
			compatible = "mediatek,dpi0";
			reg = <0x1401e000 0x1000>;
			interrupts = <0x00 0xe7 0x08>;
		};

		mm_mutex@1401f000 {
			compatible = "mediatek,mm_mutex";
			reg = <0x1401f000 0x1000>;
			interrupts = <0x00 0xca 0x08>;
		};

		smi_larb0@14020000 {
			compatible = "mediatek,smi_larb0";
			reg = <0x14020000 0x1000>;
			interrupts = <0x00 0xe9 0x08>;
		};

		smi_larb5@14021000 {
			compatible = "mediatek,smi_larb5";
			reg = <0x14021000 0x1000>;
			interrupts = <0x00 0xea 0x08>;
		};

		smi_common@14022000 {
			compatible = "mediatek,smi_common";
			reg = <0x14022000 0x1000 0x14020000 0x1000 0x16010000 0x1000 0x1a001000 0x1000 0x17001000 0x1000 0x12002000 0x1000 0x14021000 0x1000 0x15001000 0x1000>;
			clocks = <0x38 0x01 0x38 0x02 0x39 0x04 0x3a 0x07 0x3b 0x02 0x38 0x25 0x38 0x26 0x3c 0x01 0x3c 0x02 0x3c 0x03 0x3c 0x04 0x3c 0x06 0x38 0x03 0x3d 0x04 0x34 0x0d 0x34 0x05 0x34 0x04 0x34 0x0c 0x34 0x03>;
			clock-names = "smi-common\0smi-larb0\0vdec-larb1\0img-larb2\0venc-larb3\0mm-larb4\0mjc-larb4\0mjc_smi_larb\0mjc_top_clk_0\0mjc_top_clk_1\0mjc_top_clk_2\0mjc_larb4_asif\0smi-larb5\0img2-larb6\0mtcmos-ven\0mtcmos-vde\0mtcmos-isp\0mtcmos-mjc\0mtcmos-dis";
		};

		met_smi@14022000 {
			compatible = "mediatek,met_smi";
			reg = <0x14022000 0x1000 0x14020000 0x1000 0x16010000 0x1000 0x1a001000 0x1000 0x17001000 0x1000 0x12002000 0x1000 0x14021000 0x1000 0x15001000 0x1000>;
			clocks = <0x38 0x01 0x38 0x02 0x39 0x04 0x3a 0x07 0x3b 0x02 0x38 0x25 0x38 0x26 0x3c 0x01 0x3c 0x02 0x3c 0x03 0x3c 0x04 0x3c 0x06 0x38 0x03 0x3d 0x04 0x34 0x0d 0x34 0x05 0x34 0x04 0x34 0x0c 0x34 0x03>;
			clock-names = "smi-common\0smi-larb0\0vdec-larb1\0img-larb2\0venc-larb3\0mjc-larb4\0mm-larb4\0mjc_smi_larb\0mjc_top_clk_0\0mjc_top_clk_1\0mjc_top_clk_2\0mjc_larb4_asif\0smi-larb5\0img2-larb6\0mtcmos-ven\0mtcmos-vde\0mtcmos-isp\0mtcmos-mjc\0mtcmos-dis";
		};

		imgsys_config@15000000 {
			compatible = "mediatek,imgsys_config";
			reg = <0x15000000 0x1000>;
			#clock-cells = <0x01>;
			clocks = <0x34 0x03 0x38 0x01 0x34 0x04 0x3d 0x04 0x3d 0x03 0x3d 0x02 0x3d 0x01 0x3a 0x07 0x3a 0x06 0x3a 0x05 0x3a 0x04 0x3a 0x03 0x3a 0x02 0x3a 0x01>;
			clock-names = "ISP_SCP_SYS_DIS\0ISP_MM_SMI_COMMON\0ISP_SCP_SYS_ISP\0ISP_IMG_LARB6\0ISP_IMG_DIP\0ISP_IMG_DPE\0ISP_IMG_FDVT\0ISP_CAM_LARB2\0ISP_CAM_CAMSYS\0ISP_CAM_CAMTG\0ISP_CAM_SENINF\0ISP_CAM_CAMSV0\0ISP_CAM_CAMSV1\0ISP_CAM_CAMSV2";
			linux,phandle = <0x3d>;
			phandle = <0x3d>;
		};

		smi_larb6@15001000 {
			compatible = "mediatek,smi_larb6";
			reg = <0x15001000 0x1000>;
			interrupts = <0x00 0xf5 0x08>;
		};

		dip_a@15022000 {
			compatible = "mediatek,dip_a";
			reg = <0x15022000 0x4500>;
			interrupts = <0x00 0x104 0x08>;
		};

		dip_a0@15022000 {
			compatible = "mediatek,dip_a0";
			reg = <0x15022000 0x1000>;
			interrupts = <0x00 0x104 0x08>;
		};

		dip_a1@15023000 {
			compatible = "mediatek,dip_a1";
			reg = <0x15023000 0x1000>;
		};

		dip_a_nbc@15026000 {
			compatible = "mediatek,dip_a_nbc";
			reg = <0x15026000 0x1000>;
		};

		dpe@15028000 {
			compatible = "mediatek,dpe";
			reg = <0x15028000 0x1000>;
			clocks = <0x34 0x03 0x38 0x01 0x34 0x04 0x3d 0x04 0x3d 0x02>;
			clock-names = "CG_SCP_SYS_DIS\0CG_MM_SMI_COMMON\0CG_SCP_SYS_ISP\0CG_IMG_LARB6\0CG_IMG_DPE";
			interrupts = <0x00 0x105 0x08>;
		};

		fd@1502b000 {
			compatible = "mediatek,fd";
			reg = <0x1502b000 0x1000>;
			clocks = <0x34 0x03 0x38 0x01 0x34 0x04 0x3d 0x04 0x3d 0x01>;
			clock-names = "FD_CG_SCP_SYS_DIS\0FD_CG_MM_SMI_COMMON\0FD_CG_SCP_SYS_ISP\0FD_CG_IMG_LARB6\0FD_CG_IMG_FD";
			interrupts = <0x00 0x103 0x08>;
		};

		vdec_gcon@16000000 {
			compatible = "mediatek,mt6797-vdec_gcon";
			reg = <0x16000000 0x10000>;
			#clock-cells = <0x01>;
			clocks = <0x38 0x01 0x39 0x03 0x39 0x04 0x3b 0x01 0x3b 0x02 0x34 0x05 0x34 0x0d 0x34 0x03>;
			clock-names = "MT_CG_DISP0_SMI_COMMON\0MT_CG_VDEC0_VDEC\0MT_CG_VDEC1_LARB\0MT_CG_VENC_LARB\0MT_CG_VENC_VENC\0MT_SCP_SYS_VDE\0MT_SCP_SYS_VEN\0MT_SCP_SYS_DIS";
			linux,phandle = <0x39>;
			phandle = <0x39>;
		};

		smi_larb1@16010000 {
			compatible = "mediatek,smi_larb1";
			reg = <0x16010000 0x10000>;
			interrupts = <0x00 0xf1 0x08>;
		};

		vdec@16020000 {
			compatible = "mediatek,mt6797-vdec";
			reg = <0x16020000 0x10000>;
			interrupts = <0x00 0xf0 0x08>;
		};

		vld@16021000 {
			compatible = "mediatek,mt6797-vld";
			reg = <0x16021000 0x800>;
		};

		vld_top@16021800 {
			compatible = "mediatek,mt6797-vld_top";
			reg = <0x16021800 0x800>;
		};

		mc@16022000 {
			compatible = "mediatek,mt6797-mc";
			reg = <0x16022000 0x1000>;
		};

		avc_vld@16023000 {
			compatible = "mediatek,mt6797-avc_vld";
			reg = <0x16023000 0x1000>;
		};

		avc_mv@16024000 {
			compatible = "mediatek,mt6797-avc_mv";
			reg = <0x16024000 0x1000>;
		};

		vdec_pp@16025000 {
			compatible = "mediatek,mt6797-vdec_pp";
			reg = <0x16025000 0x1000>;
		};

		vp8_vld@16026800 {
			compatible = "mediatek,mt6797-vp8_vld";
			reg = <0x16026800 0x800>;
		};

		vld2@16027800 {
			compatible = "mediatek,mt6797-vld2";
			reg = <0x16027800 0x800>;
		};

		hevc_vld@16028000 {
			compatible = "mediatek,mt6797-hevc_vld";
			reg = <0x16028000 0x1000>;
		};

		venc_gcon@17000000 {
			compatible = "mediatek,mt6797-venc_gcon";
			reg = <0x17000000 0x1000>;
			#clock-cells = <0x01>;
			linux,phandle = <0x3b>;
			phandle = <0x3b>;
		};

		smi_larb3@17001000 {
			compatible = "mediatek,smi_larb3";
			reg = <0x17001000 0x1000>;
			interrupts = <0x00 0xec 0x08>;
		};

		venc@17002000 {
			compatible = "mediatek,mt6797-venc";
			reg = <0x17002000 0x1000>;
			interrupts = <0x00 0xeb 0x08>;
		};

		jpgenc@17003000 {
			compatible = "mediatek,jpgenc";
			reg = <0x17003000 0x1000>;
			interrupts = <0x00 0xed 0x08>;
			clocks = <0x34 0x03 0x38 0x01 0x34 0x0d 0x3b 0x01 0x3b 0x03>;
			clock-names = "disp-mtcmos\0disp-smi\0venc-mtcmos\0venc-larb\0venc-jpgenc";
		};

		jpgdec@17004000 {
			compatible = "mediatek,jpgdec";
			reg = <0x17004000 0x1000>;
			interrupts = <0x00 0xef 0x08>;
			clocks = <0x34 0x03 0x38 0x01 0x34 0x0d 0x3b 0x01 0x3b 0x04>;
			clock-names = "disp-mtcmos\0disp-smi\0venc-mtcmos\0venc-larb\0venc-jpgdec";
		};

		consys@18070000 {
			compatible = "mediatek,mt6797-consys";
			reg = <0x18070000 0x200 0x10007000 0x100 0x10000000 0x2000 0x10006000 0x1000>;
			interrupts = <0x00 0x11c 0x08 0x00 0x11d 0x08>;
			clocks = <0x34 0x02>;
			clock-names = "conn";
			vcn18-supply = <0x2a>;
			vcn28-supply = <0x2b>;
			vcn33_bt-supply = <0x2c>;
			vcn33_wifi-supply = <0x2d>;
			pinctrl-names = "default\0gps_lna_state_init\0gps_lna_state_oh\0gps_lna_state_ol";
			pinctrl-0 = <0x79>;
			pinctrl-1 = <0x7a>;
			pinctrl-2 = <0x7b>;
			pinctrl-3 = <0x7c>;
			status = "okay";
		};

		wifi@180f0000 {
			compatible = "mediatek,wifi";
			reg = <0x180f0000 0x1100>;
			interrupts = <0x00 0x11b 0x08>;
			clocks = <0x02 0x2e>;
			clock-names = "wifi-dma";
		};

		gic1@19000000 {
			compatible = "mediatek,gic1";
			reg = <0x19000000 0x400000>;
		};

		camsys_config@1a000000 {
			compatible = "mediatek,camsys_config";
			reg = <0x1a000000 0x1000>;
			#clock-cells = <0x01>;
			linux,phandle = <0x3a>;
			phandle = <0x3a>;
		};

		smi_larb2@1a001000 {
			compatible = "mediatek,smi_larb2";
			reg = <0x1a001000 0x1000>;
			interrupts = <0x00 0x102 0x08>;
		};

		camtop@1a003000 {
			compatible = "mediatek,camtop";
			reg = <0x1a003000 0x1000>;
			interrupts = <0x00 0xf7 0x08>;
		};

		cama@1a004000 {
			compatible = "mediatek,cama";
			reg = <0x1a004000 0x1000>;
			interrupts = <0x00 0xf8 0x08>;
		};

		camb@1a005000 {
			compatible = "mediatek,camb";
			reg = <0x1a005000 0x1000>;
			interrupts = <0x00 0xf9 0x08>;
		};

		camtop_set@1a00b000 {
			compatible = "mediatek,camtop_set";
			reg = <0x1a00b000 0x1000>;
		};

		cama_set@1a00c000 {
			compatible = "mediatek,cama_set";
			reg = <0x1a00c000 0x1000>;
		};

		camb_set@1a00d000 {
			compatible = "mediatek,camb_set";
			reg = <0x1a00d000 0x1000>;
		};

		camtop_inner@1a013000 {
			compatible = "mediatek,camtop_inner";
			reg = <0x1a013000 0x1000>;
		};

		cama_inner@1a014000 {
			compatible = "mediatek,cama_inner";
			reg = <0x1a014000 0x1000>;
		};

		camb_inner@1a015000 {
			compatible = "mediatek,camb_inner";
			reg = <0x1a015000 0x1000>;
		};

		camtop_clr@1a01b000 {
			compatible = "mediatek,camtop_clr";
			reg = <0x1a01b000 0x1000>;
		};

		cama_clr@1a01c000 {
			compatible = "mediatek,cama_clr";
			reg = <0x1a01c000 0x1000>;
		};

		camb_clr@1a01d000 {
			compatible = "mediatek,camb_clr";
			reg = <0x1a01d000 0x1000>;
		};

		seninf0@1a040000 {
			compatible = "mediatek,seninf0";
			reg = <0x1a040000 0x1000>;
		};

		kd_camera_hw1@1a040000 {
			compatible = "mediatek,camera_hw";
			reg = <0x1a040000 0x1000>;
			vcama-supply = <0x7d>;
			vcamd-supply = <0x7e>;
			vcamaf-supply = <0x7f>;
			vcamio-supply = <0x80>;
			clocks = <0x59 0x0b 0x59 0x36 0x59 0x3e>;
			clock-names = "TOP_CAMTG_SEL\0TOP_UNIVPLL_D26\0TOP_UNIVPLL2_D2";
			vcama_main2-supply = <0x7d>;
			vcama_sub-supply = <0x7d>;
			vcamd_main2-supply = <0x2e>;
			vcamd_sub-supply = <0x2e>;
			vcamio_main2-supply = <0x80>;
			vcamio_sub-supply = <0x80>;
			status = "okay";
			pinctrl-names = "default\0cam0_rst0\0cam0_rst1\0cam0_laser0\0cam0_laser1\0cam1_rst0\0cam1_rst1\0cam_ldo_vcama_0\0cam_ldo_vcama_1";
			pinctrl-0 = <0x81>;
			pinctrl-1 = <0x82>;
			pinctrl-2 = <0x83>;
			pinctrl-3 = <0x84>;
			pinctrl-4 = <0x85>;
			pinctrl-5 = <0x86>;
			pinctrl-6 = <0x87>;
			pinctrl-7 = <0x88>;
			pinctrl-8 = <0x89>;
		};

		kd_camera_hw2@1a040000 {
			compatible = "mediatek,camera_hw2";
			reg = <0x1a040000 0x1000>;
		};

		seninf1@1a041000 {
			compatible = "mediatek,seninf1";
			reg = <0x1a041000 0x1000>;
		};

		seninf2@1a042000 {
			compatible = "mediatek,seninf2";
			reg = <0x1a042000 0x1000>;
		};

		seninf3@1a043000 {
			compatible = "mediatek,seninf3";
			reg = <0x1a043000 0x1000>;
		};

		seninf4@1a044000 {
			compatible = "mediatek,seninf4";
			reg = <0x1a044000 0x1000>;
		};

		seninf5@1a045000 {
			compatible = "mediatek,seninf5";
			reg = <0x1a045000 0x1000>;
		};

		seninf6@1a046000 {
			compatible = "mediatek,seninf6";
			reg = <0x1a046000 0x1000>;
		};

		seninf7@1a047000 {
			compatible = "mediatek,seninf7";
			reg = <0x1a047000 0x1000>;
		};

		camsv00@1a050000 {
			compatible = "mediatek,camsv00";
			reg = <0x1a050000 0x1000>;
			interrupts = <0x00 0xfc 0x08>;
		};

		camsv01@1a051000 {
			compatible = "mediatek,camsv01";
			reg = <0x1a051000 0x1000>;
			interrupts = <0x00 0xfd 0x08>;
		};

		camsv10@1a052000 {
			compatible = "mediatek,camsv10";
			reg = <0x1a052000 0x1000>;
			interrupts = <0x00 0xfe 0x08>;
		};

		camsv11@1a053000 {
			compatible = "mediatek,camsv11";
			reg = <0x1a053000 0x1000>;
			interrupts = <0x00 0xff 0x08>;
		};

		camsv20@1a054000 {
			compatible = "mediatek,camsv20";
			reg = <0x1a054000 0x1000>;
			interrupts = <0x00 0x100 0x08>;
		};

		camsv21@1a055000 {
			compatible = "mediatek,camsv21";
			reg = <0x1a055000 0x1000>;
			interrupts = <0x00 0x101 0x08>;
		};

		mhl@0 {
			compatible = "mediatek,extd_dev";
		};

		gpufreq {
			compatible = "mediatek,mt6797-gpufreq";
			clocks = <0x59 0x0a 0x59 0x4e 0x59 0x29>;
			clock-names = "clk_mux\0clk_main_parent\0clk_sub_parent";
		};

		mtkfb@0 {
			compatible = "mediatek,mtkfb";
			pinctrl-names = "mode_te_gpio\0mode_te_te\0lcm_rst_out0_gpio\0lcm_rst_out1_gpio";
			pinctrl-0 = <0x8a>;
			pinctrl-1 = <0x8b>;
			pinctrl-2 = <0x8c>;
			pinctrl-3 = <0x8d>;
			vtouch-supply = <0x47>;
			lcd_bias_enp-supply = <0x8e>;
			lcd_bias_enn-supply = <0x8f>;
			status = "okay";
		};

		fpc {
			compatible = "mediatek,fpc1145";
		};

		fingerprint {
			compatible = "mediatek,goodix_fp";
			interrupt-parent = <0x33>;
			interrupts = <0x56 0x02>;
			debounce = <0x56 0x00>;
			status = "okay";
		};

		usbphy@0 {
			compatible = "usb-nop-xceiv";
		};

		vcorefs {
			compatible = "mediatek,mt6797-vcorefs";
			clocks = <0x59 0x03 0x59 0x31 0x59 0x02>;
			clock-names = "mux_axi\0syspll_d7\0mux_ulposc_axi_ck_mux";
		};

		rf_clock_buffer@0 {
			compatible = "mediatek,rf_clock_buffer";
			mediatek,clkbuf-quantity = <0x04>;
			mediatek,clkbuf-config = <0x02 0x00 0x01 0x01>;
			mediatek,clkbuf-driving-current = <0x02 0x02 0x02 0x02>;
			status = "okay";
		};

		pmic_clock_buffer@0 {
			compatible = "mediatek,pmic_clock_buffer";
			mediatek,clkbuf-quantity = <0x04>;
			mediatek,clkbuf-config = <0x00 0x00 0x00 0x00>;
			mediatek,clkbuf-drviving-current = <0x02 0x02 0x02 0x02>;
			status = "okay";
		};

		ext_buck_oc@ {
			compatible = "mediatek,mt6797-ext_buck_oc";
			status = "okay";
			interrupt-parent = <0x33>;
			interrupts = <0x3d 0x08>;
			debounce = <0x3d 0x00>;
		};

		hall_int@0 {
			compatible = "mediatek,hall_int-eint";
			interrupt-parent = <0x33>;
			interrupts = <0x40 0x08>;
			debounce = <0x40 0x7d00>;
			status = "okay";
		};

		hall_state@0 {
			compatible = "mediatek,hall";
		};

		usb_cooling_deivce@0 {
			compatible = "usb-cooling-device";
		};

		check_sim_slot@0 {
			compatible = "mediatek,check_sim_slot";
			gpio-detect-sim1-hot-plug = <0x70>;
			pinctrl-names = "default\0sim1_gpio_mode\0sim1_eint_mode";
			pinctrl-0 = <0x90>;
			pinctrl-1 = <0x91>;
			pinctrl-2 = <0x92>;
			status = "okay";
		};

		ext_buck_vproc@ {
			compatible = "mediatek,ext_buck_vproc";
			pinctrl-names = "da9214_gpio_default";
			pinctrl-0 = <0x93>;
			status = "okay";
		};

		chr_stat@ {
			compatible = "mediatek,mt6797-chr_stat";
			status = "disabled";
		};

		usbtypec_int@ {
			compatible = "mediatek,usbtypec-int";
			interrupt-parent = <0x33>;
			interrupts = <0xd2 0x08>;
			debounce = <0xd2 0x7d00>;
			status = "okay";
		};

		otg_iddig@ {
			compatible = "mediatek,usb_iddig_bi_eint";
			interrupt-parent = <0x33>;
			interrupts = <0xb5 0x08>;
		};

		touch@ {
			compatible = "mediatek,mt6797-touch";
			interrupt-parent = <0x33>;
			interrupts = <0x44 0x08>;
			debounce = <0x44 0x00>;
			status = "okay";
			irq-gpio = <0x0a 0x44 0x00>;
			irq-flags = <0x2008>;
			vtouch-supply = <0x47>;
			lcd_bias_enp-supply = <0x8e>;
			lcd_bias_enn-supply = <0x8f>;
			reset-gpio = <0x0a 0xd3 0x00>;
			reset-delay-ms = <0x64>;
			reset-active-ms = <0x14>;
			wake-gpio = <0x0a 0x43 0x00>;
			tpd-resolution = <0x438 0x780>;
			use-tpd-button = <0x00>;
			tpd-max-touch-num = <0x05>;
			tpd-filter-enable = <0x01>;
			tpd-filter-pixel-density = <0xc0>;
			tpd-filter-custom-prameters = <0x00 0x00 0x00 0x00 0x00 0x00 0x00 0x00 0x00 0x00 0x00 0x00>;
			tpd-filter-custom-speed = <0x00 0x00 0x00>;
			pinctrl-names = "default\0state_eint_as_int\0state_eint_output0\0state_eint_output1\0state_rst_output0\0state_rst_output1";
			pinctrl-0 = <0x94>;
			pinctrl-1 = <0x95>;
			pinctrl-2 = <0x96>;
			pinctrl-3 = <0x97>;
			pinctrl-4 = <0x98>;
			pinctrl-5 = <0x99>;
		};

		vow@ {
			compatible = "mediatek,vow";
		};

		sm100 {
			compatible = "mediatek,sm100";
		};

		accdet@ {
			compatible = "mediatek,mt6797-accdet";
			interrupt-parent = <0x33>;
			interrupts = <0x5c 0x08>;
			debounce = <0x5c 0x00>;
			status = "okay";
			accdet-mic-vol = <0x07>;
			headset-mode-setting = <0x500 0x500 0x01 0x1f0 0x400 0x800 0x20>;
			accdet-plugout-debounce = <0x01>;
			accdet-mic-mode = <0x01>;
			headset-three-key-threshold = <0x00 0x5a 0xaa 0x1f4>;
			headset-four-key-threshold = <0x00 0x3a 0x79 0xc0 0x190>;
			pinctrl-names = "default\0state_eint_as_int";
			pinctrl-0 = <0x9a>;
			pinctrl-1 = <0x9b>;
		};

		bat_notify {
			compatible = "mediatek,bat_notify";
		};

		battery {
			compatible = "mediatek,battery";
		};

		flashlight@ {
			compatible = "mediatek,mt6797-flashlight";
			pinctrl-names = "default\0hwen_high\0hwen_low\0torch_high\0torch_low\0flash_high\0flash_low";
			pinctrl-0 = <0x9c>;
			pinctrl-1 = <0x9d>;
			pinctrl-2 = <0x9e>;
			pinctrl-3 = <0x9f>;
			pinctrl-4 = <0xa0>;
			pinctrl-5 = <0xa1>;
			pinctrl-6 = <0xa2>;
			flashid_gpio = <0x0a 0xf8 0x00>;
			status = "okay";
		};

		gps {
			compatible = "mediatek,gps";
		};

		gps_emi {
			compatible = "mediatek,gps_emi-v1";
		};

		nfcC@0 {
			compatible = "mediatek,nfc-gpio-v2";
			gpio-ven = <0x3c>;
			gpio-rst = <0x3b>;
			gpio-eint = <0x39>;
			gpio-irq = <0x3a>;
			gpio-osc = <0x64>;
		};

		irq_nfc1@ {
			compatible = "mediatek,irq_nfc-eint";
		};

		fingerprint@ {
			compatible = "mediatek,goodix-fp";
			pinctrl-names = "default\0miso_spi\0miso_pullhigh\0miso_pulllow\0reset_high\0reset_low";
			pinctrl-0 = <0xa3>;
			pinctrl-1 = <0xa4>;
			pinctrl-2 = <0xa5>;
			pinctrl-3 = <0xa6>;
			pinctrl-4 = <0xa7>;
			pinctrl-5 = <0xa8>;
			status = "okay";
		};

		dsi_te {
			compatible = "mediatek, dsi_te-eint";
			status = "okay";
			interrupt-parent = <0x33>;
			interrupts = <0xb3 0x02>;
			debounce = <0xb3 0x00>;
		};

		chg1_int@ {
			compatible = "mediatek,charger1-eint";
			interrupt-parent = <0x33>;
			interrupts = <0x41 0x02>;
			debounce = <0x41 0x00>;
			status = "okay";
		};

		chg0_int@ {
			compatible = "mediatek,charger0-eint";
			interrupt-parent = <0x33>;
			interrupts = <0x42 0x02>;
			debounce = <0x42 0x00>;
			status = "okay";
		};

		ps_int@ {
			compatible = "mediatek,ps-eint";
			interrupt-parent = <0x33>;
			interrupts = <0x55 0x02>;
			debounce = <0x55 0x00>;
			status = "okay";
		};

		finger_print_int@ {
			compatible = "mediatek,finger_print-eint";
		};

		smartpa_int@ {
			compatible = "mediatek,smartpa-eint";
			interrupt-parent = <0x33>;
			interrupts = <0x47 0x02>;
			debounce = <0x47 0x00>;
			status = "okay";
		};

		ccci_util_cfg {
			compatible = "mediatek,ccci_util_cfg";
			mediatek,md1-smem-size = <0x200000>;
			mediatek,md3-smem-size = <0x200000>;
			mediatek,md1md3-smem-size = <0x200000>;
			mediatek,version = <0x01>;
		};

		mmc0@default {
			linux,phandle = <0x03>;
			phandle = <0x03>;

			pins_cmd {
				drive-strength = [01];
			};

			pins_dat {
				drive-strength = [01];
			};

			pins_clk {
				drive-strength = [01];
			};

			pins_rst {
				drive-strength = [01];
			};

			pins_ds {
				drive-strength = [01];
			};
		};

		mmc0@register_default {
			dat0rddly = [00];
			dat1rddly = [00];
			dat2rddly = [00];
			dat3rddly = [00];
			dat4rddly = [00];
			dat5rddly = [00];
			dat6rddly = [00];
			dat7rddly = [00];
			datwrddly = [00];
			cmdrrddly = [00];
			cmdrddly = [00];
			cmd_edge = [01];
			rdata_edge = [01];
			wdata_edge = [01];
			linux,phandle = <0x04>;
			phandle = <0x04>;
		};

		mmc1@default {
			linux,phandle = <0x05>;
			phandle = <0x05>;

			pins_cmd {
				drive-strength = [06];
			};

			pins_dat {
				drive-strength = [06];
			};

			pins_clk {
				drive-strength = [06];
			};
		};

		mmc1@sdr104 {
			linux,phandle = <0x06>;
			phandle = <0x06>;

			pins_cmd {
				drive-strength = [03];
			};

			pins_dat {
				drive-strength = [03];
			};

			pins_clk {
				drive-strength = [04];
			};
		};

		mmc1@sdr50 {
			linux,phandle = <0x07>;
			phandle = <0x07>;

			pins_cmd {
				drive-strength = [03];
			};

			pins_dat {
				drive-strength = [03];
			};

			pins_clk {
				drive-strength = [04];
			};
		};

		mmc1@ddr50 {
			linux,phandle = <0x08>;
			phandle = <0x08>;

			pins_cmd {
				drive-strength = [03];
			};

			pins_dat {
				drive-strength = [03];
			};

			pins_clk {
				drive-strength = [04];
			};
		};

		mmc1@register_default {
			dat0rddly = [00];
			dat1rddly = [00];
			dat2rddly = [00];
			dat3rddly = [00];
			datwrddly = [00];
			cmdrrddly = [00];
			cmdrddly = [00];
			cmd_edge = [01];
			rdata_edge = [01];
			wdata_edge = [01];
			linux,phandle = <0x09>;
			phandle = <0x09>;
		};

		tpvddi {
			compatible = "pinctrl-regulator";
			pinctrl-names = "on_cfg\0off_cfg";
			pinctrl-0 = <0xa9>;
			pinctrl-1 = <0xaa>;
			regulator-name = "tpvddi";
			regulator-min-microvolt = <0x1b7740>;
			regulator-max-microvolt = <0x1b7740>;
			regulator-ramp-delay = <0xfa>;
			regulator-enable-ramp-delay = <0xb4>;
			regulator-boot-on = <0x01>;
			linux,phandle = <0x47>;
			phandle = <0x47>;
		};

		lcd_enp {
			compatible = "pinctrl-regulator";
			pinctrl-names = "on_cfg\0off_cfg";
			pinctrl-0 = <0xab>;
			pinctrl-1 = <0xac>;
			regulator-name = "lcd_enp";
			regulator-min-microvolt = <0x588040>;
			regulator-max-microvolt = <0x588040>;
			regulator-ramp-delay = <0xfa>;
			regulator-enable-ramp-delay = <0xb4>;
			regulator-boot-on = <0x01>;
			linux,phandle = <0x8e>;
			phandle = <0x8e>;
		};

		lcd_enn {
			compatible = "pinctrl-regulator";
			pinctrl-names = "on_cfg\0off_cfg";
			pinctrl-0 = <0xad>;
			pinctrl-1 = <0xae>;
			regulator-name = "lcd_enn";
			regulator-min-microvolt = <0x588040>;
			regulator-max-microvolt = <0x588040>;
			regulator-ramp-delay = <0xfa>;
			regulator-enable-ramp-delay = <0xb4>;
			regulator-boot-on = <0x01>;
			linux,phandle = <0x8f>;
			phandle = <0x8f>;
		};
	};

	hwmsensor@0 {
		compatible = "mediatek,hwmsensor";
	};

	gsensor@0 {
		compatible = "mediatek,gsensor";
	};

	m_acc_pl@0 {
		compatible = "mediatek,m_acc_pl";
	};

	acc_gyro_0@0 {
		compatible = "mediatek,acc_gyro_0";
		interrupt-parent = <0x33>;
		interrupts = <0x3f 0x02>;
		debounce = <0x3f 0x00>;
		status = "okay";
	};

	acc_gyro_1@0 {
		compatible = "mediatek,acc_gyro_1";
		interrupt-parent = <0x33>;
		interrupts = <0x59 0x02>;
		debounce = <0x59 0x00>;
		status = "okay";
	};

	pressure@0 {
		compatible = "mediatek,pressure";
	};

	als_ps@0 {
		compatible = "mediatek,als_ps";
		interrupt-parent = <0x33>;
		interrupts = <0x5a 0x02>;
		debounce = <0x5a 0x00>;
		status = "okay";
		pinctrl-names = "pin_default\0pin_cfg";
		pinctrl-0 = <0xaf>;
		pinctrl-1 = <0xb0>;
	};

	m_alsps_pl@0 {
		compatible = "mediatek,m_alsps_pl";
	};

	m_batch_pl@0 {
		compatible = "mediatek,m_batch_pl";
	};

	batchsensor@0 {
		compatible = "mediatek,batchsensor";
	};

	gyroscope@0 {
		compatible = "mediatek,gyroscope";
		pinctrl-names = "pin_default\0pin_cfg";
		pinctrl-0 = <0xb1>;
		pinctrl-1 = <0xb2>;
		status = "okay";
	};

	pdrsensor@0 {
		compatible = "mediatek,pdrsensor";
	};

	uncali_gyro@0 {
		compatible = "mediatek,uncali_gyro";
	};

	m_gyro_pl@0 {
		compatible = "mediatek,m_gyro_pl";
	};

	barometer@0 {
		compatible = "mediatek,barometer";
	};

	m_baro_pl@0 {
		compatible = "mediatek,m_baro_pl";
	};

	humidity@0 {
		compatible = "mediatek,humidity";
	};

	m_hmdy_pl@0 {
		compatible = "mediatek,m_hmdy_pl";
	};

	msensor@0 {
		compatible = "mediatek,msensor";
	};

	uncali_mag@0 {
		compatible = "mediatek,uncali_mag";
	};

	m_mag_pl@0 {
		compatible = "mediatek,m_mag_pl";
	};

	orientation@0 {
		compatible = "mediatek,orientation";
	};

	pedometer@0 {
		compatible = "mediatek,pedometer";
	};

	wake_gesture@0 {
		compatible = "mediatek,wake_gesture";
	};

	pick_up@0 {
		compatible = "mediatek,pick_up";
	};

	glance_gesture@0 {
		compatible = "mediatek,glance_gesture";
	};

	tilt@0 {
		compatible = "mediatek,tilt_detector";
	};

	answer_call@0 {
		compatible = "mediatek,answer_call";
	};

	activity@0 {
		compatible = "mediatek,activity";
	};

	step_counter@0 {
		compatible = "mediatek,step_counter";
	};

	rotationvector@0 {
		compatible = "mediatek,rotationvector";
	};

	gamerotvec@0 {
		compatible = "mediatek,gamerotvec";
	};

	gmagrotvec@0 {
		compatible = "mediatek,gmagrotvec";
	};

	linearaccel@0 {
		compatible = "mediatek,linearaccel";
	};

	gravity@0 {
		compatible = "mediatek,gravity";
	};

	scp_sensorHub@0 {
		compatible = "mediatek,sensorHub";
	};

	shf {
		compatible = "mediatek,shf";
	};

	cam_cal_drv {
		compatible = "mediatek,cam_cal_drv";
		main_bus = <0x03>;
		sub_bus = <0x03>;
	};

	trusty {
		compatible = "android,trusty-smc-v1";
		ranges;
		#address-cells = <0x02>;
		#size-cells = <0x02>;

		irq {
			compatible = "android,trusty-irq-v1";
			ppi-interrupt-parent = <0x01>;
		};

		log {
			compatible = "android,trusty-log-v1";
		};

		virtio {
			compatible = "android,trusty-virtio-v1";
		};

		mtee {
			compatible = "mediatek,trusty-mtee-v1";
		};
	};

	memory@40000000 {
		device_type = "memory";
		reg = <0x00 0x40000000 0x00 0x1e605000>;
	};

	firmware {

		android {
			compatible = "android,firmware";

			fstab {
				compatible = "android,fstab";

				system {
					compatible = "android,system";
					dev = "/dev/block/platform/mtk-msdc.0/11230000.msdc0/by-name/system";
					type = "ext4";
					mnt_flags = "ro,barrier=1";
					fsmgr_flags = "wait";
					status = "ok";
				};

				vendor {
					compatible = "android,vendor";
					dev = "/dev/block/platform/mtk-msdc.0/11230000.msdc0/by-name/custom";
					type = "ext4";
					mnt_flags = "ro,barrier=1";
					fsmgr_flags = "wait";
					status = "ok";
				};
			};
		};
	};

	led@0 {
		compatible = "mediatek,red";
		led_mode = <0x00>;
		data = <0x01>;
		pwm_config = <0x00 0x00 0x00 0x00 0x00>;
	};

	led@1 {
		compatible = "mediatek,green";
		led_mode = <0x00>;
		data = <0x01>;
		pwm_config = <0x00 0x00 0x00 0x00 0x00>;
	};

	led@2 {
		compatible = "mediatek,blue";
		led_mode = <0x00>;
		data = <0x01>;
		pwm_config = <0x00 0x00 0x00 0x00 0x00>;
	};

	led@3 {
		compatible = "mediatek,jogball-backlight";
		led_mode = <0x00>;
		data = <0x01>;
		pwm_config = <0x00 0x00 0x00 0x00 0x00>;
	};

	led@4 {
		compatible = "mediatek,keyboard-backlight";
		led_mode = <0x00>;
		data = <0x01>;
		pwm_config = <0x00 0x00 0x00 0x00 0x00>;
	};

	led@5 {
		compatible = "mediatek,mx-led";
		led_mode = <0x03>;
		data = <0x01>;
		pwm_config = <0x00 0x00 0x00 0x00 0x00>;
	};

	led@6 {
		compatible = "mediatek,lcd-backlight";
		led_mode = <0x04>;
		data = <0x01>;
		pwm_config = <0x00 0x00 0x00 0x00 0x00>;
	};

	vibrator@0 {
		compatible = "mediatek,vibrator";
		vib_timer = <0x19>;
		vib_limit = <0x09>;
		vib_vol = <0x05>;
	};

	cust_accel@0 {
		compatible = "mediatek,icm20645g";
		i2c_num = <0x01>;
		i2c_addr = <0x68 0x00 0x00 0x00>;
		direction = <0x03>;
		power_id = <0xffff>;
		power_vol = <0x00>;
		firlen = <0x00>;
		is_batch_supported = <0x00>;
	};

	cust_alsps@0 {
		compatible = "mediatek,cm36558";
		i2c_num = <0x01>;
		i2c_addr = <0x51 0x00 0x00 0x00>;
		polling_mode_ps = <0x00>;
		polling_mode_als = <0x01>;
		power_id = <0xffff>;
		power_vol = <0x00>;
		als_level = <0x00 0x148 0x35d 0x561 0xc35 0x1e29 0x1e57 0x314d 0x5a16 0x6f0e 0x81fa 0xb80c 0xe15e 0xe15e 0xffff>;
		als_value = <0x00 0x85 0x130 0x1f6 0x3ec 0x7d5 0xbf2 0x138d 0x1f48 0x271a 0x2ee0 0x3e80 0x4e20 0x4e20 0x4e20 0x4e20>;
		ps_threshold_high = <0x1a>;
		ps_threshold_low = <0x15>;
		is_batch_supported_ps = <0x00>;
		is_batch_supported_als = <0x00>;
	};

	cust_mag@0 {
		compatible = "mediatek,akm09912";
		i2c_num = <0x01>;
		i2c_addr = <0x0c 0x00 0x00 0x00>;
		direction = <0x07>;
		power_id = <0xffff>;
		power_vol = <0x00>;
		is_batch_supported = <0x00>;
	};

	cust_gyro@0 {
		compatible = "mediatek,icm20645gy";
		i2c_num = <0x01>;
		i2c_addr = <0x69 0x00 0x00 0x00>;
		direction = <0x03>;
		power_id = <0xffff>;
		power_vol = <0x00>;
		firlen = <0x00>;
		is_batch_supported = <0x00>;
	};

	cust_baro@0 {
		compatible = "mediatek,bmp280";
		i2c_num = <0x01>;
		i2c_addr = <0x77 0x00 0x00 0x00>;
		direction = <0x00>;
		power_id = <0xffff>;
		power_vol = <0x00>;
		firlen = <0x00>;
		is_batch_supported = <0x00>;
	};

	cust_hmdy@0 {
		compatible = "mediatek,hts221";
		i2c_num = <0x01>;
		i2c_addr = <0x5f 0x00 0x00 0x00>;
		direction = <0x00>;
		power_id = <0xffff>;
		power_vol = <0x00>;
		firlen = <0x00>;
		is_batch_supported = <0x00>;
	};
};
